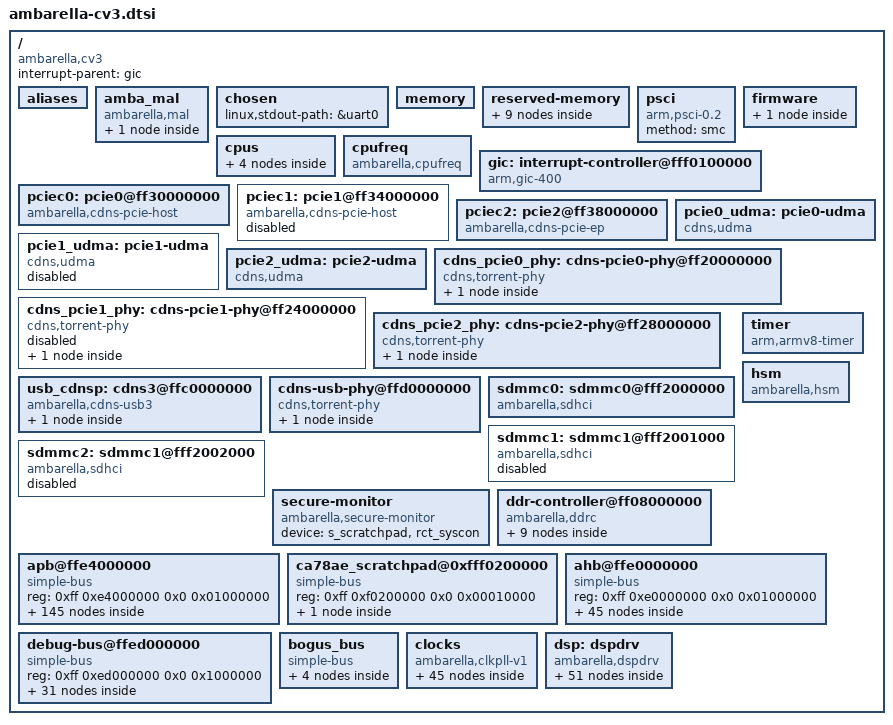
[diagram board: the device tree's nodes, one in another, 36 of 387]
/*
 * chip level device tree source include
 */

/ {
	compatible = "ambarella,cv3";
	interrupt-parent = <&gic>;
	#address-cells = <2>;
	#size-cells = <2>;

	aliases {
		serial0 = &uart0;
		serial1 = &uart1;
		serial2 = &uart2;
		serial3 = &uart3;
		serial4 = &uart4;
		nand = &nand0;
		sd0 = &sdmmc0;
		sd1 = &sdmmc1;
		sd2 = &sdmmc2;
		/* for emmc boot: add emmc alias */
		emmc = &sdmmc0;
		spinor = &spinor0;
		i2c0 = &i2c0;
		i2c1 = &i2c1;
		i2c2 = &i2c2;
		i2c3 = &i2c3;
		i2c4 = &i2c4;
		i2c5 = &i2c5;
		i2cs = &i2cs;
		spi0 = &spi0;
		spi1 = &spi1;
		spi2 = &spi2;
		spi3 = &spi3;
		spi4 = &spi4;
		spi5 = &spi5;
		ethernet0 = &mac0;
		ethernet1 = &mac1;
		ethernet2 = &mac2;
		ethernet3 = &mac3;
		dsp_prot_buf = &dsp_prot_buf;
		dsp_prot_cache_buf = &dsp_prot_cache_buf;
		dsp_bin_buf = &dsp_bin_buf;
		dsp_data_buf = &dsp_data_buf;
		dsp = &dsp;
	};

	amba_mal {
		compatible = "ambarella,mal";
		amb_mal_node@ff {
			memory-region = <&pio>;
			amb_mal_id = <0x07>;
			dedicate-alloc;
		};
	};

	chosen: chosen {
		linux,stdout-path = &uart0;
	};

	/*
	 * the memory node will be overwritten in Amboot,
	 * here is just the default value.
	 */
	memory {
		device_type = "memory";
	};

	reserved-memory {
		#address-cells = <2>;
		#size-cells = <2>;
		device_type = "reserved-memory";
		ranges;

		/* 0~16KB for internal use, like profiling */
		sdk_reserved {
			compatible = "shared-dma-pool";
			no-map;
			reg = <0x0 0x0 0x0 0x4000>;
		};
		pcie0_rmem: pcie0_rmem {
		};
		pcie2_rmem: pcie2_rmem {
		};
		pio: pio {
		};
		xtb {
		};
		dsp_prot_buf: dsp_prot_buf {
		};
		dsp_prot_cache_buf: dsp_prot_cache_buf {
		};
		dsp_bin_buf: dsp_bin_buf {
		};
		dsp_data_buf: dsp_data_buf {
		};
	};

	psci {
		compatible = "arm,psci-0.2";
		method = "smc";
	};

	firmware {
		optee {
			compatible = "linaro,optee-tz";
			method = "smc";
			status = "disabled";
		};
	};

/*
	pmu {
		compatible = "arm,cortex-a78-pmu";
		interrupts = <0 3 0x4>,
			     <0 4 0x4>;
	};
*/

	cpus {
		#address-cells = <1>;
		#size-cells = <0>;

		cpu@0 {
			compatible = "arm,cortex-a78", "arm,armv8";
			device_type = "cpu";
			reg = <0x000>;
			enable-method = "psci";
		};

		cpu@1 {
			compatible = "arm,cortex-a78", "arm,armv8";
			device_type = "cpu";
			reg = <0x100>;
			enable-method = "psci";
		};

		cpu@2 {
			compatible = "arm,cortex-a78", "arm,armv8";
			device_type = "cpu";
			reg = <0x200>;
			enable-method = "psci";
		};

		cpu@3 {
			compatible = "arm,cortex-a78", "arm,armv8";
			device_type = "cpu";
			reg = <0x300>;
			enable-method = "psci";
		};
	};

	cpufreq {
		compatible = "ambarella,cpufreq";

		/*
		 * MASK
		 * + --- + ----- + ----- +
		 * | bit |   1   |   0   |
		 * + --- + ----- + ----- +
		 * | clk |  CORE | CORTEX|
		 * + --- + ----- + ----- +
		 */
		cpufreq-mask = <1>;
		amb,timer-freq-adjust-off;
		clocks = <&gclk_cortex &gclk_core>;
		clock-names = "cortex_clk", "core_clk";
		clocks-frequency-cortex-core =
			<1008000  504000>,
			<816000  336000>,
			<600000  240000>;
	};

	gic: interrupt-controller@fff0100000 {
		compatible = "arm,gic-400";
		#interrupt-cells = <3>;
		#address-cells = <0>;
		#size-cells = <1>;
		interrupt-controller;
		reg = <0xff 0xf0101000 0x0 0x1000>,	/* GIC Dist */
		      <0xff 0xf0102000 0x0 0x2000>,	/* GIC CPU */
		      /* following are not used if no virtulization */
		      <0xff 0xf0104000 0x0 0x2000>,	/* GIC VCPU Control */
		      <0xff 0xf0106000 0x0 0x2000>;	/* GIC VCPU */
		interrupts = <1 9 0xf04>;		/* GIC Maintenence IRQ */
	};

	/*
	 * NOTE: Don't remove "pcie0" in device name("pcie0@ff30000000"),
	 *       it is used to select correct uDMA in endpoint function
	 *       or rc drivers.
	 */
	pciec0: pcie0@ff30000000 {
		compatible = "ambarella,cdns-pcie-host";
		device_type = "pci";
		#address-cells = <3>;
		#size-cells = <2>;
		#interrupt-cells = <1>;
		bus-range = <0 15>;
		linux,pci-domain = <0>;

		reg = <0xff 0x30000000 0x0 0x00600000>,
		      <0xff 0x10000000 0x0 0x00100000>;	/* RC only */
		reg-names = "reg", "cfg";
		memory-region = <&pcie0_rmem>;

		/*
		 * type: 0x01000000 IO
		 * type: 0x02000000 32bit mem space No prefetch
		 * type: 0x03000000 64bit mem space No prefetch
		 * type: 0x43000000 64bit mem space prefetch
		 */
		ranges = <0x02000000 0x00 0x00000000 0xff 0x11000000 0x00 0x01000000>,
			 <0x43000000 0xff 0x12000000 0xff 0x12000000 0x00 0x08000000>;

		interrupt-map-mask = <0x00 0x0 0x0 0x7>;
		interrupt-map = <0x0 0x0 0x0 0x1 &gic 0 202 0x4>,
				<0x0 0x0 0x0 0x2 &gic 0 203 0x4>,
				<0x0 0x0 0x0 0x3 &gic 0 204 0x4>,
				<0x0 0x0 0x0 0x4 &gic 0 205 0x4>;

		cdns,no-bar-match-nbits = <40>;		// RC only
		cdns,max-outbound-regions = <8>;	// EP only
		max-functions = /bits/ 8 <1>;		// EP only

		amb,scr-regmap = <&n_scratchpad_syscon 0x1ac>;
		phys = <&pcie0_phy>;
		phy-names="pcie-phy";
	};

	/*
	 * NOTE: Don't remove "pcie1" in device name("pcie1@ff34000000"),
	 *       it is used to select correct uDMA in endpoint function
	 *       or rc drivers.
	 */
	pciec1: pcie1@ff34000000 {
		compatible = "ambarella,cdns-pcie-host";
		device_type = "pci";
		#address-cells = <3>;
		#size-cells = <2>;
		#interrupt-cells = <1>;
		bus-range = <0 15>;
		linux,pci-domain = <1>;

		reg = <0xff 0x34000000 0x0 0x00600000>,
		      <0xff 0x50000000 0x0 0x00100000>;
		reg-names = "reg", "cfg";

		ranges = <0x02000000 0x00 0x00000000 0xff 0x51000000 0x00 0x01000000>,
			 <0x43000000 0xff 0x52000000 0xff 0x52000000 0x00 0x08000000>;

		interrupt-map-mask = <0x00 0x0 0x0 0x7>;
		interrupt-map = <0x0 0x0 0x0 0x1 &gic 0 216 0x4>,
				<0x0 0x0 0x0 0x2 &gic 0 217 0x4>,
				<0x0 0x0 0x0 0x3 &gic 0 218 0x4>,
				<0x0 0x0 0x0 0x4 &gic 0 219 0x4>;

		cdns,no-bar-match-nbits = <40>;

		amb,scr-regmap = <&n_scratchpad_syscon 0x1b0>;
		phys = <&pcie1_phy>;
		phy-names="pcie-phy";

		status = "disabled";
	};

	/*
	 * NOTE: Don't remove "pcie2" in device name("pcie2@ff38000000"),
	 *       it is used to select correct uDMA in endpoint function
	 *       or rc drivers.
	 */
	pciec2: pcie2@ff38000000 {
		compatible = "ambarella,cdns-pcie-ep";
		device_type = "pci";
		#address-cells = <3>;
		#size-cells = <2>;
		#interrupt-cells = <1>;
		bus-range = <0 15>;
		linux,pci-domain = <2>;

		reg = <0xff 0x38000000 0x0 0x00600000>,
		      <0xff 0x90000000 0x0 0x30000000>;
		reg-names = "reg", "mem";
		memory-region = <&pcie2_rmem>;

		interrupt-map-mask = <0x00 0x0 0x0 0x7>;
		interrupt-map = <0x0 0x0 0x0 0x1 &gic 0 230 0x4>,
				<0x0 0x0 0x0 0x2 &gic 0 231 0x4>,
				<0x0 0x0 0x0 0x3 &gic 0 232 0x4>,
				<0x0 0x0 0x0 0x4 &gic 0 233 0x4>;

		cdns,no-bar-match-nbits = <40>;		// RC only

		amb,scr-regmap = <&n_scratchpad_syscon 0x1b4>;
		phys = <&pcie2_phy>;
		phy-names="pcie-phy";

		status = "okay";
	};

	pcie0_udma: pcie0-udma {
		#address-cells = <2>;
		#size-cells = <2>;
		compatible = "cdns,udma";
		interrupts = <0 200 0x4>;
		reg = <0xff 0x30600000 0x0 0x000000fc>;
		status = "okay";
	};

	pcie1_udma: pcie1-udma {
		#address-cells = <2>;
		#size-cells = <2>;
		compatible = "cdns,udma";
		interrupts = <0 214 0x4>;
		reg = <0xff 0x34600000 0x0 0x000000fc>;
		status = "disabled";
	};

	pcie2_udma: pcie2-udma {
		#address-cells = <2>;
		#size-cells = <2>;
		compatible = "cdns,udma";
		interrupts = <0 228 0x4>;
		reg = <0xff 0x38600000 0x0 0x000000fc>;
		status = "okay";
	};

	cdns_pcie0_phy: cdns-pcie0-phy@ff20000000 {
		compatible = "cdns,torrent-phy";
		#address-cells = <1>;
		#size-cells = <0>;
		reg = <0xff 0x20000000 0x0 0x04000000>;

		resets = <&pcie0_phyrst 0>;
		reset-names = "torrent_reset";

		clocks = <&cdns_phy_refclk>;
		clock-names = "refclk";

		pcie0_phy: phy@0 {
			reg = <0>;
			resets=<&pcie0_phyrst 1>;	// link reset not used
			#phy-cells= <0>;
			cdns,phy-type = <2>;		// TYPE_PCIE
			cdns,num-lanes = <4>;
			cdns,ssc-mode = <0>;		// NO_SSC
		};
	};

	cdns_pcie1_phy: cdns-pcie1-phy@ff24000000 {
		compatible = "cdns,torrent-phy";
		#address-cells = <1>;
		#size-cells = <0>;
		reg = <0xff 0x24000000 0x0 0x04000000>;

		resets = <&pcie1_phyrst 0>;
		reset-names = "torrent_reset";

		clocks = <&cdns_phy_refclk>;
		clock-names = "refclk";

		status = "disabled";

		pcie1_phy: phy@0 {
			reg = <0>;
			resets=<&pcie1_phyrst 1>;	// link reset not used
			#phy-cells= <0>;
			cdns,phy-type = <2>;		// TYPE_PCIE
			cdns,num-lanes = <4>;
			cdns,ssc-mode = <0>;		// NO_SSC
		};
	};

	cdns_pcie2_phy: cdns-pcie2-phy@ff28000000 {
		compatible = "cdns,torrent-phy";
		#address-cells = <1>;
		#size-cells = <0>;
		reg = <0xff 0x28000000 0x0 0x04000000>;

		resets = <&pcie2_phyrst 0>;
		reset-names = "torrent_reset";

		clocks = <&cdns_phy_refclk>;
		clock-names = "refclk";

		status = "okay";

		pcie2_phy: phy@0 {
			reg = <0>;
			resets=<&pcie2_phyrst 1>;	// link reset not used
			#phy-cells= <0>;
			cdns,phy-type = <2>;		// TYPE_PCIE
			cdns,num-lanes = <4>;
			cdns,ssc-mode = <0>;		// NO_SSC
		};
	};

	usb_cdnsp: cdns3@ffc0000000 {
		compatible = "ambarella,cdns-usb3";
		#address-cells = <2>;
		#size-cells = <2>;
		reg = <0xff 0xc0000000 0x0 0x10000000>;
		ranges;
		amb,scr-regmap = <&n_scratchpad_syscon>;

		cdns3: cdns3 {
			compatible = "cdns,usb3";
			interrupts = <0 190 0x4>, <0 190 0x4>, <0 190 0x4>;
			interrupt-names = "host", "peripheral", "otg";
			reg = <0xff 0xc0008000 0x0 0x4000>,
			      <0xff 0xc0004000 0x0 0x4000>,
			      <0xff 0xc0000000 0x0 0x4000>;
			reg-names = "xhci", "dev", "otg";
			dr_mode = "otg";
			phys = <&usb32_phy>;
			phy-names = "cdns3,usb3-phy";
			maximum-speed = "super-speed-plus";
			usb-role-switch;
		};
	};

	cdns-usb-phy@ffd0000000 {
		compatible = "cdns,torrent-phy";
		#address-cells = <1>;
		#size-cells = <0>;
		reg = <0xff 0xd0000000 0x0 0x00100000>;

		clocks = <&cdns_phy_refclk>;
		clock-names = "refclk";

		resets = <&usb32_phyrst 0>;
		reset-names = "torrent_reset";

		usb32_phy: phy@0 {
			reg = <0>;
			resets = <&usb32_phyrst 1>;
			#phy-cells = <0>;
			cdns,phy-type = <4>;	/* TYPE_USB */
			cdns,num-lanes = <1>;
			cdns,ssc-mode = <2>;	/* INTERNAL_SSC */
		};
	};

	sdmmc0: sdmmc0@fff2000000 {
		compatible = "ambarella,sdhci";
		//Modify start byte addr and size to 64bits.
		#address-cells = <2>;
		#size-cells = <2>;
		reg = <0xff 0xf2000000 0x0 0x1000>;
		interrupts = <0 109 0x4>;
		clocks = <&gclk_sd0>;
		bus-width = <8>;
		cap-sdio-irq;
		cap-sd-highspeed;
		cap-mmc-highspeed;
		mmc-hs200-1_8v;
	};

	sdmmc1: sdmmc1@fff2001000 { /* SDIO0 */
		compatible = "ambarella,sdhci";
		reg = <0xff 0xf2001000 0x0 0x1000>;
		interrupts = <0 110 0x4>;
		clocks = <&gclk_sd1>;
		bus-width = <4>;
		cap-sdio-irq;
		cap-sd-highspeed;
		cap-mmc-highspeed;
		status = "disabled";
	};

	sdmmc2: sdmmc1@fff2002000 { /* SDIO1 */
		compatible = "ambarella,sdhci";
		reg = <0xff 0xf2002000 0x0 0x1000>;
		interrupts = <0 111 0x4>;
		clocks = <&gclk_sd2>;
		bus-width = <4>;
		cap-sdio-irq;
		cap-sd-highspeed;
		cap-mmc-highspeed;
		status = "disabled";
	};

	timer {
		compatible = "arm,armv8-timer";
		interrupts = <1 13 0xf08>,	/* Secure Phys IRQ */
			     <1 14 0xf08>,	/* Non-secure Phys IRQ */
			     <1 11 0xf08>,	/* Virt IRQ */
			     <1 10 0xf08>;	/* Hyp IRQ */
	};

	secure-monitor {
		compatible = "ambarella,secure-monitor";
		#address-cells = <1>;
		#size-cells = <0>;
		device = <&s_scratchpad &rct_syscon>;
	};

	ddr-controller@ff08000000 {
		compatible = "ambarella,ddrc";
		#address-cells = <1>;
		#size-cells = <1>;
		reg = <0xff 0x08000000 0x0 0x80000>;
		burst-size = <0>;		/* This property will be overwritten in AMBOOT. */

		dramc: dramc@08000000 {
			reg = <0x08000000 0x1000>;
        };

        /* DDR host controller cluster */
		ddrhc0: ddrhc0@08014000 {
			reg = <0x08014000 0x2000>;
			compatible = "ambarella,dtte";
			interrupts = <0 254 0x4>;
			interrupt-names = "dtte0";
        };
		ddrhc1: ddrhc1@08020000 {
			reg = <0x08020000 0x2000>;
			compatible = "ambarella,dtte";
			interrupts = <0 255 0x4>;
			interrupt-names = "dtte1";
        };
		ddrhc2: ddrhc2@0802c000 {
			reg = <0x0802c000 0x2000>;
			compatible = "ambarella,dtte";
			interrupts = <0 256 0x4>;
			interrupt-names = "dtte2";
        };
		ddrhc3: ddrhc3@08038000 {
			reg = <0x08038000 0x2000>;
			compatible = "ambarella,dtte";
			interrupts = <0 257 0x4>;
			interrupt-names = "dtte3";
        };
		ddrhc4: ddrhc4@08044000 {
			reg = <0x08044000 0x2000>;
			compatible = "ambarella,dtte";
			interrupts = <0 258 0x4>;
			interrupt-names = "dtte4";
        };
		ddrhc5: ddrhc5@08050000 {
			reg = <0x08050000 0x2000>;
			compatible = "ambarella,dtte";
			interrupts = <0 259 0x4>;
			interrupt-names = "dtte5";
        };
		ddrhc6: ddrhc6@0805c000 {
			reg = <0x0805c000 0x2000>;
			compatible = "ambarella,dtte";
			interrupts = <0 260 0x4>;
			interrupt-names = "dtte6";
        };
		ddrhc7: ddrhc7@08068000 {
			reg = <0x08068000 0x2000>;
			compatible = "ambarella,dtte";
			interrupts = <0 261 0x4>;
			interrupt-names = "dtte7";
        };
	};

	apb@ffe4000000 {
		compatible = "simple-bus";
		#address-cells = <1>;
		#size-cells = <1>;
		reg = <0xff 0xe4000000 0x0 0x01000000>;
		ranges = <0xe4000000 0xff 0xe4000000 0x01000000>;

		clocksource1: timer@e4004054 {	/* timer6 */
			compatible = "ambarella,clock-source";
			reg = <0xe4004054 0x10 0xe4004030 0x4>;
			interrupts = <0 158 0x1>;
			ctrl-offset = <20>; /* bit offset in timer-ctrl reg */
			clocks = <&gclk_apb>;
			status = "disabled";
		};

		clockevent1: timer@e4004064 {	/* timer7, timer8, timer9, timer10 */
			compatible = "ambarella,local-clock-event";
			reg = <0xe4004064 0x10 0xe4004030 0x4>,
			      <0xe4004074 0x10 0xe4004030 0x4>,
			      <0xe4004088 0x10 0xe4004084 0x4>,
			      <0xe4004098 0x10 0xe4004084 0x4>;
			interrupts = <0 159 0x1>, <0 160 0x1>, <0 161 0x1>, <0 162 0x1>;
			ctrl-offset = <24 28 00 04>; /* bit offset in timer-ctrl reg */
			clocks = <&gclk_apb>;
			status = "disabled";
		};

		clocksource2: timer@e4005054 {	/* timer16 */
			compatible = "ambarella,clock-source";
			reg = <0xe4005054 0x10 0xe4005030 0x4>;
			interrupts = <0 168 0x1>;
			ctrl-offset = <20>; /* bit offset in timer-ctrl reg */
			clocks = <&gclk_apb>;
			status = "disabled";
		};

		clockevent2: timer@e4005064 {	/* timer17, timer18, timer19, timer20 */
			compatible = "ambarella,local-clock-event";
			reg = <0xe4005064 0x10 0xe4005030 0x4>,
			      <0xe4005074 0x10 0xe4005030 0x4>,
			      <0xe4005088 0x10 0xe4005084 0x4>,
			      <0xe4005098 0x10 0xe4005084 0x4>;
			interrupts = <0 169 0x1>, <0 170 0x1>, <0 171 0x1>, <0 172 0x1>;
			ctrl-offset = <24 28 00 04>; /* bit offset in timer-ctrl reg */
			clocks = <&gclk_apb>;
			status = "disabled";
		};

		clocksource3: timer@e4006054 {	/* timer26 */
			compatible = "ambarella,clock-source";
			reg = <0xe4006054 0x10 0xe4006030 0x4>;
			interrupts = <0 464 0x1>;
			ctrl-offset = <20>; /* bit offset in timer-ctrl reg */
			clocks = <&gclk_apb>;
			status = "disabled";
		};

		clockevent3: timer@e4006044 {	/* timer27, timer28, timer29, timer30 */
			compatible = "ambarella,local-clock-event";
			reg = <0xe4006064 0x10 0xe4006030 0x4>,
			      <0xe4006074 0x10 0xe4006030 0x4>,
			      <0xe4006088 0x10 0xe4006084 0x4>,
			      <0xe4006098 0x10 0xe4006084 0x4>;
			interrupts = <0 465 0x1>, <0 466 0x1>, <0 467 0x1>, <0 468 0x1>;
			ctrl-offset = <24 28 00 04>; /* bit offset in timer-ctrl reg */
			clocks = <&gclk_apb>;
			status = "disabled";
		};

		uart0: uart@e4000000 {
			compatible = "ambarella,uart";
			reg = <0xe4000000 0x1000>;
			interrupts = <0 187 0x4>;
			pinctrl-names = "default";
			pinctrl-0 = <&uart0_pins>;
			clocks = <&gclk_uart0>;
			status = "ok";
		};

		ir@e4001000 {
			compatible = "ambarella,ir";
			reg = <0xe4001000 0x1000>;
			interrupts = <0 189 0x4>;
			pinctrl-names = "default";
			pinctrl-0 = <&ir_pins_a>;
			clocks = <&gclk_ir>;
			status = "disabled";
		};

		i2c0: i2c@e4008000 {
			compatible = "ambarella,i2c";
			#address-cells = <1>;
			#size-cells = <0>;
			reg = <0xe4008000 0x1000>;
			interrupts = <0 173 0x4>;
			pinctrl-names = "default";
			pinctrl-0 = <&i2c0_pins>;
			clocks = <&gclk_apb>;
			clock-frequency = <100000>;
			amb,i2c-class = <0x81>;
			status = "disabled";
		};

		i2c1: i2c@e4009000 {
			compatible = "ambarella,i2c";
			#address-cells = <1>;
			#size-cells = <0>;
			reg = <0xe4009000 0x1000>;
			interrupts = <0 174 0x4>;
			pinctrl-names = "default";
			pinctrl-0 = <&i2c1_pins_c>;
			clocks = <&gclk_apb>;
			clock-frequency = <100000>;
			amb,i2c-class = <0x08>;
			status = "disabled";
		};

		i2c2: i2c@e400a000 {
			compatible = "ambarella,i2c";
			#address-cells = <1>;
			#size-cells = <0>;
			reg = <0xe400a000 0x1000>;
			interrupts = <0 175 0x4>;
			clocks = <&gclk_apb>;
			pinctrl-names = "default";
			pinctrl-0 = <&i2c2_pins_b>;
			clock-frequency = <100000>;
			amb,i2c-class = <0x81>;
			status = "disabled";
		};

		i2c3: i2c@e400b000 {
			compatible = "ambarella,i2c";
			#address-cells = <1>;
			#size-cells = <0>;
			reg = <0xe400b000 0x1000>;
			interrupts = <0 176 0x4>;
			clocks = <&gclk_apb>;
			pinctrl-names = "default";
			pinctrl-0 = <&i2c3_pins_a>;
			clock-frequency = <100000>;
			amb,i2c-class = <0x81>;
			status = "disabled";
		};

		i2c4: i2c@e400e000 {
			compatible = "ambarella,i2c";
			#address-cells = <1>;
			#size-cells = <0>;
			reg = <0xe400e000 0x1000>;
			interrupts = <0 177 0x4>;
			clocks = <&gclk_apb>;
			pinctrl-names = "default";
			pinctrl-0 = <&i2c4_pins_a>;
			clock-frequency = <100000>;
			amb,i2c-class = <0x81>;
			status = "disabled";
		};

		i2c5: i2c@e400f000 {
			compatible = "ambarella,i2c";
			#address-cells = <1>;
			#size-cells = <0>;
			reg = <0xe400f000 0x1000>;
			interrupts = <0 178 0x4>;
			clocks = <&gclk_apb>;
			pinctrl-names = "default";
			pinctrl-0 = <&i2c5_pins_c>;
			clock-frequency = <100000>;
			amb,i2c-class = <0x81>;
			status = "disabled";
		};

		i2cs: i2cs@e4007000 {
			compatible = "ambarella,i2cs";
			#address-cells = <1>;
			#size-cells = <0>;
			reg = <0xe4007000 0x1000>;
			interrupts = <0 179 0x4>;
			clocks = <&gclk_apb>;
			pinctrl-names = "default";
			pinctrl-0 = <&i2cs0_pins>;
			status = "disabled";
		};

		pwm0: pwm@e4003000 {
			compatible = "ambarella,pwm";
			reg = <0xe4003000 0x1000>;
			clock-frequency = <2000000>;
			clocks = <&gclk_pwm>;
			#pwm-cells = <3>;
		};

		pwm1: pwm@e400c000 {
			compatible = "ambarella,pwm";
			reg = <0xe400c000 0x1000>;
			clock-frequency = <2000000>;
			clocks = <&gclk_pwm>;
			#pwm-cells = <3>;
		};

		pwm2: pwm@e400d000 {
			compatible = "ambarella,pwm";
			reg = <0xe400d000 0x1000>;
			clock-frequency = <2000000>;
			clocks = <&gclk_pwm>;
			#pwm-cells = <3>;
		};

		watchdog0: wdt@e401a000 {
			compatible = "ambarella,wdt";
			reg = <0xe401a000 0x1000>;
			/* interrupts = <0 469 0x4>; */
			timeout-sec = <15>;
			amb,rct-regmap = <&rct_syscon>;
			amb,secure-ctrl-bit = <117>;
		};

		watchdog1: wdt@e401b000 {
			compatible = "ambarella,wdt";
			reg = <0xe401b000 0x1000>;
			/* interrupts = <0 470 0x4>; */
			timeout-sec = <15>;
			amb,rct-regmap = <&rct_syscon>;
			amb,secure-ctrl-bit = <118>;
		};

		watchdog2: wdt@e401c000 {
			compatible = "ambarella,wdt";
			reg = <0xe401c000 0x1000>;
			/* interrupts = <0 471 0x4>; */
			timeout-sec = <15>;
			amb,rct-regmap = <&rct_syscon>;
			amb,secure-ctrl-bit = <119>;
		};

		watchdog3: wdt@e401d000 {
			compatible = "ambarella,wdt";
			reg = <0xe401d000 0x1000>;
			/* interrupts = <0 472 0x4>; */
			timeout-sec = <15>;
			amb,rct-regmap = <&rct_syscon>;
			amb,secure-ctrl-bit = <120>;
		};

		watchdog4: wdt@e401e000 {
			compatible = "ambarella,wdt";
			reg = <0xe401e000 0x1000>;
			/* interrupts = <0 473 0x4>; */
			timeout-sec = <15>;
			amb,rct-regmap = <&rct_syscon>;
			amb,secure-ctrl-bit = <121>;
		};

		watchdog5: wdt@e401f000 {
			compatible = "ambarella,wdt";
			reg = <0xe401f000 0x1000>;
			/* interrupts = <0 474 0x4>; */
			timeout-sec = <15>;
			amb,rct-regmap = <&rct_syscon>;
			amb,secure-ctrl-bit = <122>;
		};

		watchdog6: wdt@e4020000 {
			compatible = "ambarella,wdt";
			reg = <0xe4020000 0x1000>;
			/* interrupts = <0 475 0x4>; */
			timeout-sec = <15>;
			amb,rct-regmap = <&rct_syscon>;
			amb,secure-ctrl-bit = <123>;
		};

		watchdog7: wdt@e4021000 {
			compatible = "ambarella,wdt";
			reg = <0xe4021000 0x1000>;
			/* interrupts = <0 476 0x4>; */
			timeout-sec = <15>;
			amb,rct-regmap = <&rct_syscon>;
			amb,secure-ctrl-bit = <124>;
		};

		pinctrl: pinctrl@e4010000 {
			compatible = "ambarella,pinctrl";
			#address-cells = <1>;
			#size-cells = <0>;
			reg = <0xe4013000 0x1000>,
			      <0xe4014000 0x1000>,
			      <0xe4015000 0x1000>,
			      <0xe4016000 0x1000>,
			      <0xe4017000 0x1000>,
			      <0xe4018000 0x1000>,
			      <0xe4019000 0x1000>,
			      <0xe4010000 0x1000>;
			reg-names = "gpio0", "gpio1", "gpio2", "gpio3", "gpio4","gpio5","gpio6","iomux";
			interrupts = <0 180 0x4>,
				     <0 181 0x4>,
				     <0 182 0x4>,
				     <0 183 0x4>,
				     <0 184 0x4>,
				     <0 185 0x4>,
				     <0 186 0x4>;
			amb,pull-regmap = <&s_scratchpad 0x60 0x7c>;
			amb,ds-regmap = <&rct_syscon>;
			amb,secure-ctrl-bit = <50 51 52 53 54 59 37 48>;

			gpio: gpio@0 {
				reg = <0>;
				gpio-controller;
				#gpio-cells = <2>;
				gpio-ranges = <&pinctrl 0 0 213>;
				interrupt-controller;
				#interrupt-cells = <2>;
			};

			uart0_pins: uart0@0 {
				reg = <0>;
				amb,pinmux-ids = <0x102d 0x102e>;
			};

			uart1_pins_a: uart1@0 {		/* UART0_AHB_TX/RX */
				reg = <0>;
				amb,pinmux-ids = <0x3050 0x3051>;
			};

			uart1_pins_b: uart1@1 {
				reg = <1>;
				amb,pinmux-ids = <0x109f 0x10a0>;
			};

			uart1_flow_pins_a: uart1_flow@0 {
				reg = <0>;
				amb,pinmux-ids = <0x3053 0x3054>;
			};

			uart1_flow_pins_b: uart1_flow@1 {
				reg = <1>;
				amb,pinmux-ids = <0x10a1 0x10a2>;
			};

			uart2_pins_a: uart2@0 {		/* UART1_AHB_RX/RX */
				reg = <0>;
				amb,pinmux-ids = <0x10a3 0x10a4>;
			};

			uart2_pins_b: uart2@1 {
				reg = <1>;
				amb,pinmux-ids = <0x30a7 0x30a8>;
			};

			uart2_flow_pins_a: uart2_flow@0 {
				reg = <0>;
				amb,pinmux-ids = <0x10a5 0x10a6>;
			};

			uart2_flow_pins_b: uart2_flow@1 {
				reg = <1>;
				amb,pinmux-ids = <0x30a9 0x30aa>;
			};

			uart3_pins_a: uart3@0 {		/* UART2_AHB_RX/RX */
				reg = <0>;
				amb,pinmux-ids = <0x207a 0x207b>;
			};

			uart3_pins_b: uart3@1 {
				reg = <1>;
				amb,pinmux-ids = <0x2084 0x2085>;
			};

			uart3_pins_c: uart3@2 {
				reg = <2>;
				amb,pinmux-ids = <0x20cf 0x20d0>;
			};

			uart3_flow_pins_a: uart3_flow@0 {
				reg = <0>;
				amb,pinmux-ids = <0x207c 0x207d>;
			};

			uart3_flow_pins_b: uart3_flow@1 {
				reg = <1>;
				amb,pinmux-ids = <0x2086 0x2087>;
			};

			uart3_flow_pins_c: uart3_flow@2 {
				reg = <2>;
				amb,pinmux-ids = <0x20d1 0x20d2>;
			};

			uart4_pins_a: uart4@0 {		/* UART3_AHB_RX/RX */
				reg = <0>;
				amb,pinmux-ids = <0x2089 0x208a>;
			};

			uart4_pins_b: uart4@1 {
				reg = <1>;
				amb,pinmux-ids = <0x406a 0x406b>;
			};

			uart4_pins_c: uart4@2 {
				reg = <2>;
				amb,pinmux-ids = <0x30cf 0x30d0>;
			};

			uart4_flow_pins_a: uart4_flow@0 {
				reg = <0>;
				amb,pinmux-ids = <0x208b 0x208c>;
			};

			uart4_flow_pins_b: uart4_flow@1 {
				reg = <1>;
				amb,pinmux-ids = <0x406c 0x406d>;
			};

			uart4_flow_pins_c: uart4_flow@2 {
				reg = <2>;
				amb,pinmux-ids = <0x30d1 0x30d2>;
			};

			snand_pins: snand@0 {
				reg = <0>;
				amb,pinmux-ids = <0x1078 0x1079 0x107a 0x107b
						  0x107c 0x107d>;
			};

			spinor_pins: spinor@0 {
				reg = <0>;
				amb,pinmux-ids = <0x107e 0x107f 0x1080 0x1081
						  0x1082 0x1083 0x1084 0x1085
						  0x1086 0x1087 0x1088>;
			};

			sdmmc0_reset_pin: sdmmc0_reset@0 {
				reg = <0>;
				amb,pinmux-ids = <0x1090>;
			};

			sdmmc1_reset_pin: sdmmc1_reset@0 {
				reg = <0>;
				amb,pinmux-ids = <0x1092>;
			};

			sdmmc2_reset_pin: sdmmc2_reset@0 {
				reg = <0>;
				amb,pinmux-ids = <0x1094>;
			};

			enet_ext_osc_clk: enet-ext-osc-clk@0 {	/* shared by enet0/1/2/3 125MHZ input refclock */
				reg = <0>;
				amb,pinmux-ids = <0x2049>;
			};

			enet_2nd_ref_clk_a: enet-2nd-ref-clk@0 {
				reg = <0>;
				amb,pinmux-ids = <0x1048>;
			};

			enet_2nd_ref_clk_b: enet-2nd-ref-clk@1 {
				reg = <1>;
				amb,pinmux-ids = <0x104a>;
			};

			enet_2nd_ref_clk_c: enet-2nd-ref-clk@2 {
				reg = <2>;
				amb,pinmux-ids = <0x204a>;
			};

			enet_2nd_ref_clk_d: enet-2nd-ref-clk@3 {
				reg = <3>;
				amb,pinmux-ids = <0x1059>;
			};

			enet_2nd_ref_clk_e: enet-2nd-ref-clk@4 {
				reg = <4>;
				amb,pinmux-ids = <0x1068>;
			};

			enet_2nd_ref_clk_f: enet-2nd-ref-clk@5 {
				reg = <5>;
				amb,pinmux-ids = <0x1077>;
			};

			rgmii0_pins: eth0@0 {	/* ethernet-mac0 */
				reg = <0>;
				amb,pinmux-ids = <0x203a 0x203b 0x203c 0x203d
						  0x203e 0x203f 0x2040 0x2041
						  0x2042 0x2043	0x3044 0x3045
						  0x2047 0x2048>;
			};

			rmii0_pins: eth0@1 {
				reg = <1>;
				amb,pinmux-ids = <0x103a 0x103b 0x103c 0x103f
						  0x1040 0x1043 0x3044 0x3045 0x1047>;
			};

			rgmii0_ptp_pps_o: enet0-ptp-pps-o@0 {
				reg = <0>;
				amb,pinmux-ids = <0x2046>;
			};

			rmii0_ptp_pps_o: enet0-ptp-pps-o@1 {
				reg = <1>;
				amb,pinmux-ids = <0x1046>;
			};

			rgmii1_pins: eth1@0 {	/* ethernet-mac1 */
				reg = <0>;
				amb,pinmux-ids = <0x204b 0x204c 0x204d 0x204e
						  0x204f 0x2050 0x2051 0x2052
						  0x2053 0x2054 0x3055 0x3056
						  0x2058 0x2059>;

			};

			rmii1_pins: eth1@1 {
				reg = <1>;
				amb,pinmux-ids = <0x104b 0x104c 0x104d 0x1050
						  0x1051 0x1054 0x3055 0x3056
						  0x1058>;
			};

			rgmii1_ptp_pps_o: enet1-ptp-pps-o@0 {
				reg = <0>;
				amb,pinmux-ids = <0x2057>;
			};

			rmii1_ptp_pps_o: enet1-ptp-pps-o@1 {
				reg = <1>;
				amb,pinmux-ids = <0x1057>;
			};

			rgmii2_pins: eth2@0 {	/* ethernet-mac2 */
				reg = <0>;
				amb,pinmux-ids = <0x205a 0x205b 0x205c 0x205d
						  0x205e 0x205f 0x2060 0x2061
						  0x2062 0x2063 0x3064 0x3065
						  0x2067 0x2068>;
			};

			rmii2_pins: eth2@1 {
				reg = <1>;
				amb,pinmux-ids = <0x105a 0x105b 0x105c 0x105f
						  0x1060 0x1063 0x3064 0x3065
						  0x1067>;
			};

			rgmii2_ptp_pps_o: enet2-ptp-pps-o@0 {
				reg = <0>;
				amb,pinmux-ids = <0x2066>;
			};

			rmii2_ptp_pps_o: enet2-ptp-pps-o@1 {
				reg = <1>;
				amb,pinmux-ids = <0x1066>;
			};

			rgmii3_pins: eth3@0 {	/* ethernet-mac3 */
				reg = <0>;
				amb,pinmux-ids = <0x2069 0x206a 0x206b 0x206c
						  0x206d 0x206e 0x206f 0x2070
						  0x2071 0x2072 0x3073 0x3074
						  0x2076 0x2077>;
			};

			rmii3_pins: eth3@1 {
				reg = <1>;
				amb,pinmux-ids = <0x1069 0x106a 0x106b 0x106e
						  0x106f 0x1072 0x3073 0x3074
						  0x1076>;
			};

			rgmii3_ptp_pps_o: enet3-ptp-pps-o@0 {
				reg = <0>;
				amb,pinmux-ids = <0x2075>;
			};

			rmii3_ptp_pps_o: enet3-ptp-pps-o@1 {
				reg = <1>;
				amb,pinmux-ids = <0x1075>;
			};

			i2c0_pins: i2c0@0 {
				reg = <0>;
				amb,pinmux-ids = <0x109a 0x109b>;
			};

			i2c1_pins_a: i2c1@0 {
				reg = <0>;
				amb,pinmux-ids = <0x2002 0x2003>;
			};

			i2c1_pins_b: i2c1@1 {
				reg = <1>;
				amb,pinmux-ids = <0x405f 0x4060>;
			};

			i2c1_pins_c: i2c1@2 {
				reg = <2>;
				amb,pinmux-ids = <0x40cf 0x40d0>;
			};

			i2c2_pins_a: i2c2@0 {
				reg = <0>;
				amb,pinmux-ids = <0x2004 0x2005>;
			};

			i2c2_pins_b: i2c2@1 {
				reg = <1>;
				amb,pinmux-ids = <0x1098 0x1099>;
			};

			i2c2_pins_c: i2c2@2 {
				reg = <2>;
				amb,pinmux-ids = <0x40d1 0x40d2>;
			};

			i2c3_pins_a: i2c3@0 {
				reg = <0>;
				amb,pinmux-ids = <0x200b 0x200c>;
			};

			i2c3_pins_b: i2c3@1 {
				reg = <1>;
				amb,pinmux-ids = <0x20a5 0x20a6>;
			};

			i2c3_pins_c: i2c3@2 {
				reg = <2>;
				amb,pinmux-ids = <0x50a7 0x50a8>;
			};

			i2c4_pins_a: i2c4@0 {
				reg = <0>;
				amb,pinmux-ids = <0x200d 0x200e>;
			};

			i2c4_pins_b: i2c4@1 {
				reg = <1>;
				amb,pinmux-ids = <0x4050 0x4051>;
			};

			i2c4_pins_c: i2c4@2 {
				reg = <2>;
				amb,pinmux-ids = <0x4061 0x4062>;
			};

			i2c5_pins_a: i2c5@0 {
				reg = <0>;
				amb,pinmux-ids = <0x4052 0x4053>;
			};

			i2c5_pins_b: i2c5@1 {
				reg = <1>;
				amb,pinmux-ids = <0x5066 0x5067>;
			};

			i2c5_pins_c: i2c5@2 {
				reg = <2>;
				amb,pinmux-ids = <0x30a5 0x30a6>;
			};

			i2cs0_pins: i2cs0@0 {
				reg = <0>;
				amb,pinmux-ids = <0x1013 0x1014>;
			};

			can0_pins: can0@0 {
				reg = <0>;
				amb,pinmux-ids = <0x10a7 0x10a8>;
			};

			can1_pins: can1@0 {
				reg = <0>;
				amb,pinmux-ids = <0x10a9 0x10aa>;
			};

			ir_pins_a: ir0@0 {
				reg = <0>;
				amb,pinmux-ids = <0x1000>;
			};

			ir_pins_b: ir0@1 {
				reg = <1>;
				amb,pinmux-ids = <0x5058>;
			};

			ir_pins_c: ir0@2 {
				reg = <2>;
				amb,pinmux-ids = <0x3063>;
			};

			wdt_pins_a: wdt0@0 {
				reg = <0>;
				amb,pinmux-ids = <0x2000>;
			};

			wdt_pins_b: wdt0@1 {
				reg = <1>;
				amb,pinmux-ids = <0x2001>;
			};

			wdt_pins_c: wdt0@2 {
				reg = <2>;
				amb,pinmux-ids = <0x2006>;
			};

			wdt_pins_d: wdt0@3 {
				reg = <3>;
				amb,pinmux-ids = <0x303a>;
			};

			wdt_pins_e: wdt0@4 {
				reg = <4>;
				amb,pinmux-ids = <0x304b>;
			};

			wdt_pins_f: wdt0@5 {
				reg = <5>;
				amb,pinmux-ids = <0x209c>;
			};

			wdt_pins_g: wdt0@6 {
				reg = <6>;
				amb,pinmux-ids = <0x409f>;
			};

			wdt_pins_h: wdt0@7 {
				reg = <7>;
				amb,pinmux-ids = <0x40d4>;
			};

			i2s0_pins: i2s0@0 {
				reg = <0>;
				amb,pinmux-ids = <0x1032 0x1033 0x1034 0x1035>;
			};

			i2s1_pins: i2s1@0 {
				reg = <0>;
				amb,pinmux-ids = <0x1036 0x1037 0x1038 0x1039>;
			};

			dmic0_pins: dmic_pins@0 {
				reg = <0>;
				amb,pinmux-ids = <0x2032 0x2033>;
			};

			pwm0_pins: pwm0@0 {
				reg = <0>;
				amb,pinmux-ids = <0x102f>;
			};

			pwm1_pins: pwm1@0 {
				reg = <0>;
				amb,pinmux-ids = <0x1030>;
			};

			pwm2_pins: pwm2@0 {
				reg = <0>;
				amb,pinmux-ids = <0x1031>;
			};

			pwm3_pins_a: pwm3@0 {
				reg = <0>;
				amb,pinmux-ids = <0x2007>;
			};

			pwm3_pins_b: pwm3@1 {
				reg = <1>;
				amb,pinmux-ids = <0x2029>;
			};

			pwm4_pins_a: pwm4@0 {
				reg = <0>;
				amb,pinmux-ids = <0x2008>;
			};

			pwm4_pins_b: pwm4@1 {
				reg = <1>;
				amb,pinmux-ids = <0x202a>;
			};

			pwm5_pins_a: pwm5@0 {
				reg = <0>;
				amb,pinmux-ids = <0x2009>;
			};

			pwm5_pins_b: pwm5@1 {
				reg = <1>;
				amb,pinmux-ids = <0x202b>;
			};

			pwm6_pins_a: pwm6@0 {
				reg = <0>;
				amb,pinmux-ids = <0x200a>;
			};

			pwm6_pins_b: pwm6@1 {
				reg = <1>;
				amb,pinmux-ids = <0x202c>;
			};

			pwm7_pins_a: pwm7@0 {
				reg = <0>;
				amb,pinmux-ids = <0x2015>;
			};

			pwm7_pins_b: pwm7@1 {
				reg = <1>;
				amb,pinmux-ids = <0x10cf>;
			};

			pwm8_pins_a: pwm8@0 {
				reg = <0>;
				amb,pinmux-ids = <0x2016>;
			};

			pwm8_pins_b: pwm8@1 {
				reg = <1>;
				amb,pinmux-ids = <0x10d0>;
			};

			pwm9_pins_a: pwm9@0 {
				reg = <0>;
				amb,pinmux-ids = <0x2017>;
			};

			pwm9_pins_b: pwm9@1 {
				reg = <1>;
				amb,pinmux-ids = <0x10d1>;
			};

			pwm10_pins_a: pwm10@0 {
				reg = <0>;
				amb,pinmux-ids = <0x2018>;
			};

			pwm10_pins_b: pwm10@1 {
				reg = <1>;
				amb,pinmux-ids = <0x10d2>;
			};

			pwm11_pins_a: pwm11@0 {
				reg = <0>;
				amb,pinmux-ids = <0x2019>;
			};

			pwm11_pins_b: pwm11@1 {
				reg = <1>;
				amb,pinmux-ids = <0x10d3>;
			};

			spi0_pins: spi0@0 {
				reg = <0>;
				amb,pinmux-ids = <0x1002 0x1003 0x1004>;
			};

			spi1_pins: spi1@0 {
				reg = <0>;
				amb,pinmux-ids = <0x1007 0x1008 0x1009>;
			};

			spi2_pins_a: spi2@0 {
				reg = <0>;
				amb,pinmux-ids = <0x100b 0x100c 0x100d>;
			};

			spi2_pins_b: spi2@1 {
				reg = <1>;
				amb,pinmux-ids = <0x405b 0x405c 0x405d>;
			};

			spi3_pins_a: spi3@0 {
				reg = <0>;
				amb,pinmux-ids = <0x200f 0x2010 0x2011>;
			};

			spi3_pins_b: spi3@1 {
				reg = <1>;
				amb,pinmux-ids = <0x303f 0x3040 0x3041>;
			};

			spi3_pins_c: spi3@2 {
				reg = <2>;
				amb,pinmux-ids = <0x306a 0x306b 0x306c>;
			};

			spi4_pins_a: spi4@0 {
				reg = <0>;
				amb,pinmux-ids = <0x3043 0x3046 0x3047>;
			};

			spi4_pins_b: spi4@1 {
				reg = <1>;
				amb,pinmux-ids = <0x305b 0x305c 0x305d>;
			};

			spi4_pins_c: spi4@2 {
				reg = <2>;
				amb,pinmux-ids = <0x50cf 0x50d0 0x50d1>;
			};

			spi5_pins_a: spi5@0 {
				reg = <0>;
				amb,pinmux-ids = <0x304d 0x304f 0x3050>;
			};

			spi5_pins_b: spi5@1 {
				reg = <1>;
				amb,pinmux-ids = <0x305f 0x3061 0x3062>;
			};

			spi5_pins_c: spi5@2 {
				reg = <2>;
				amb,pinmux-ids = <0x40a7 0x40a9 0x40aa>;
			};

			spi_slave_pins: spi_slave@0 {
				reg = <0>;
				amb,pinmux-ids = <0x100f 0x1010 0x1011 0x1012>;
			};
		};
	};

	ca78ae_scratchpad@0xfff0200000 {
		compatible = "simple-bus";
		#address-cells = <1>;
		#size-cells = <1>;
		reg = <0xff 0xf0200000 0x0 0x00010000>;
		ranges = <0xf0200000 0xff 0xf0200000 0x00010000>;

		ca78ae_scratchpad_syscon: ca78ae_scratchpad_syscon@f0200000 {
			compatible = "ambarella,ca78ae-scratchpad", "syscon";
			reg = <0xf0200000 0x10000>;
		};
	};

	hsm {
		compatible = "ambarella,hsm";
		#address-cells = <1>;
		#size-cells = <1>;
		interrupts = <0 28 0x1>, <0 29 0x1>, <0 30 0x1>;
		interrupt-names = "dram_comm0", "dram_comm1", "dram_comm2";
		domain = "SAFETY";
		scr-regmap = <&ca78ae_scratchpad_syscon>;
	};

	ahb@ffe0000000 {
		compatible = "simple-bus";
		#address-cells = <1>;
		#size-cells = <1>;
		reg = <0xff 0xe0000000 0x0 0x01000000>;
		ranges = <0xe0000000 0xff 0xe0000000 0x01000000>;

		n_scratchpad_syscon: scratchpad_syscon@e0024000 {
			compatible = "ambarella,nsec-scratchpad", "syscon";
			reg = <0xe0024000 0x1000>;
		};

		/* note: use s_scratchpad@xxx for unique naming */
		s_scratchpad: s_scratchpad@e002e000 {
			compatible = "ambarella,sec-scratchpad", "syscon";
			reg = <0xe002e000 0x1000>;
			amb,secure-ctrl-bit = <31>;
		};

		cpuid_syscon: cpuid@e0000000 {
			compatible = "ambarella,cpuid", "syscon";
			reg = <0xe0000000 0x1000>;
		};

		pcie0_phyrst: pcie0-phyrst {
			compatible = "ambarella,pcie-phyrst";
			#reset-cells = <1>;
			amb,scr-regmap = <&n_scratchpad_syscon 0x180 0x190 0x194>;
			amb,pcie-controller = <&pciec0>;
			amb,pcie-phy-id = <0>;
		};

		pcie1_phyrst: pcie1-phyrst {
			compatible = "ambarella,pcie-phyrst";
			#reset-cells = <1>;
			amb,scr-regmap = <&n_scratchpad_syscon 0x184 0x190 0x198>;
			amb,pcie-controller = <&pciec1>;
			amb,pcie-phy-id = <1>;
			status = "disabled";
		};

		pcie2_phyrst: pcie2-phyrst {
			compatible = "ambarella,pcie-phyrst";
			#reset-cells = <1>;
			amb,scr-regmap = <&n_scratchpad_syscon 0x188 0x190 0x19c>;
			amb,pcie-controller = <&pciec2>;
			amb,pcie-phy-id = <2>;
			status = "okay";
		};

		usb32_phyrst: usb32-phyrst {
			compatible = "ambarella,usb32-phyrst";
			#reset-cells = <1>;
			amb,scr-regmap = <&n_scratchpad_syscon 0x154 0x174 0x16c>;
		};

		spinor0: spinor@e0001000 {
			compatible = "ambarella,spinor";
			reg = <0xe0001000 0x1000>;
			interrupts = <0 134 0x4>;
			pinctrl-names = "default";
			pinctrl-0 = <&spinor_pins>;
			clocks = <&gclk_ssi3>;
			dmas = <&dma0 5>, <&dma0 6>;
			dma-names = "tx", "rx";
			max-frequency = <50000000>;
			status = "disabled";
		};

		nand0: nand@e0002000 {
			compatible = "ambarella,nand";
			reg = <0xe0002000 0x1000>;
			interrupts = <0 132 0x4>;
			pinctrl-names = "default";
			pinctrl-0 = <&snand_pins>;
			clocks = <&gclk_nand>;
			nand-on-flash-bbt;
			/* amb,soft-ecc = <6>; */
		};

		udc0: udc@e0006000 {
			compatible = "ambarella,udc";
			reg = <0xe0006000 0x2000>;
			interrupts = <0 126 0x4>;
			amb,scr-regmap = <&n_scratchpad_syscon 25>;
			amb,usbphy = <&usbphy>;
		};

		dma0: dma@e0020000 {
			compatible = "ambarella,dma";
			reg = <0xe0020000 0x1000>;
			interrupts = <0 146 0x4>;
			#dma-cells = <1>;
			dma-channels = <8>;
			dma-requests = <29>;
			amb,scr-regmap = <&s_scratchpad 0x2c 0xc4>;
		};

		dma1: dma@e0021000 {
			compatible = "ambarella,dma";
			reg = <0xe0021000 0x1000>;
			interrupts = <0 147 0x4>;
			#dma-cells = <1>;
			dma-channels = <8>;
			dma-requests = <29>;
			amb,scr-regmap = <&s_scratchpad 0xc8 0xcc>;
		};

		dma2: dma@e0029000 {
			compatible = "ambarella,dma";
			reg = <0xe0029000 0x1000>;
			interrupts = <0 148 0x4>;
			#dma-cells = <1>;
			dma-channels = <8>;
			dma-requests = <29>;
			amb,scr-regmap = <&s_scratchpad 0x24 0x28>;
		};

		gdma0: gdma@e000b000 {
			compatible = "ambarella,gdma";
			reg = <0xe000b000 0x1000>;
			interrupts = <0 103 0x1>;
		};

		gdma1: gdma@e001b000 {
			compatible = "ambarella,gdma";
			reg = <0xe001b000 0x1000>;
			interrupts = <0 104 0x1>;
		};

		gdma2: gdma@e001e000 {
			compatible = "ambarella,gdma";
			reg = <0xe001e000 0x1000>;
			interrupts = <0 105 0x1>;
		};

		gdma3: gdma@e001f000 {
			compatible = "ambarella,gdma";
			reg = <0xe001f000 0x1000>;
			interrupts = <0 106 0x1>;
		};

		i2s0: i2s@e001c000 {
			compatible = "ambarella,i2s";
			#sound-dai-cells = <0>;
			reg = <0xe001c000 0x1000>;
			pinctrl-names = "default";
			pinctrl-0 = <&i2s0_pins>;
			clocks = <&gclk_audio>;
			amb,i2s-channels = <2>;
			amb,default-mclk = <12288000>;
			dmas = <&dma0 21>, <&dma0 22>;
			dma-names = "tx", "rx";
			amb,ws-set;
			amb,clk-au-enable;
			amb,scr-regmap = <&n_scratchpad_syscon 0x110>;
			status = "disabled";
		};

		i2s1: i2s@e001d000 {
			compatible = "ambarella,i2s";
			#sound-dai-cells = <0>;
			reg = <0xe001d000 0x1000>;
			pinctrl-names = "default";
			pinctrl-0 = <&i2s1_pins>;
			clocks = <&gclk_audio2>;
			amb,i2s-channels = <2>;
			amb,default-mclk = <12288000>;
			dmas = <&dma0 23>, <&dma0 24>;
			dma-names = "tx", "rx";
			amb,ws-set;
			amb,clk-au-enable;
			amb,scr-regmap = <&n_scratchpad_syscon 0x110>;
			status = "disabled";
		};

		stmmac_axi_setup: stmmac-axi-config {
			/* enable IS_ENABLED(CONFIG_ARCH_DMA_ADDR_T_64BIT) to enable 40bits dma
			   descriptor must be within 4GB.  buffer-addr can be 40bit
			 */
			snps,wr_osr_lmt = <0x4>;	/* cv3:max 8 Ref DMA_SysBus_Mode */
			snps,rd_osr_lmt = <0x4>;	/* cv3:max 8 Ref DMA_SysBus_Mode */
			snps,blen = <256 128 64 32 0 0 0>;	/* when FB=0,last 3 item has no mean */
		};

		mtl_rx_setup: rx-queues-config {
			snps,rx-queues-to-use = <1>;
			snps,rx-sched-sp;
			queue0 {
				snps,dcb-algorithm;		/* data-center-bridge */
				snps,map-to-dma-channel = <0x0>;
				snps,priority = <0x0>;
			};

			/*
			queue1 {
				snps,dcb-algorithm;
				snps,map-to-dma-channel = <0x1>;
				snps,priority = <0x1>;
			};*/
		};

		mtl_tx_setup: tx-queues-config {
			snps,tx-queues-to-use = <1>;
			snps,tx-sched-wrr;			/* schedule-algo wrr */
			queue0 {
				snps,dcb-algorithm;
				snps,weight = <0x10>;
				snps,priority = <0x0>;
			};

			/*
			queue1 {
				snps,dcb-algorithm;
				snps,weight = <0x20>;
				snps,priority = <0x1>;
			};
			*/
		};

		/* mac version 5.20  */
		mac0: ethernet@e000e000 {
			compatible = "ambarella-dwmac-eqos","snps,dwmac-5.10a","snps,dwmac";
			#address-cells = <1>;
			#size-cells = <0>;
			reg = <0xe000e000 0x2000>;
			interrupt-parent = <&gic>;
			interrupts = <0 96 0x4>,<0 95 0x4>,<0 91 0x4>;
			interrupt-names="macirq","eth_wake_irq","eth_lpi";

			snps,multicast-filter-bins = <64>;
			snps,perfect-filter-entries = <3>;
			rx-fifo-depth = <8192>;
			tx-fifo-depth = <16384>;
			clocks = <&pll_out_enet>, <&osc>;	/* ptp_ref from ??? */
			clock-names = "stmmaceth","ptp_ref";
			max-speed = <1000>;			/* max_1000M */

			snps,tso;
			snps,pbl=<32>;
			snps,no-pbl-x8;
			snps,fixed-burst;
			/*
			 * normal: snps,force_sf_dma_mode;
			 * max-frame-size = <1500>; mtu=1500;
			 * jumbo : snps,force_thresh_dma_mode
			*/
			/*snps,force_sf_dma_mode;*/
			snps,axi-config = <&stmmac_axi_setup>;
			snps,mtl-rx-config = <&mtl_rx_setup>;
			snps,mtl-tx-config = <&mtl_tx_setup>;

			amb,ahb-12mhz-div = <5>;
			amb,tx-clk-invert;
			amb,rct-regmap = <&rct_syscon>;
			amb,scr-regmap = <&n_scratchpad_syscon>;
			amb,dma-eame;	/* must ENABLED(CONFIG_ARCH_DMA_ADDR_T_64BIT) to use 40bits dma */
			pinctrl-names = "default";
			pinctrl-0 = <&rgmii0_pins &enet_ext_osc_clk &enet_2nd_ref_clk_c>;
			snps,ps-speed=<1000>;	/* RGMII_SPeed:10/100/1000 base_on enet_ext_osc_clk(2.5M/25M/125M) */
			status = "disabled";
		};

		mac1: ethernet@e0022000 {
			compatible = "ambarella-dwmac-eqos","snps,dwmac-5.10a","snps,dwmac";
			#address-cells = <1>;
			#size-cells = <0>;
			reg = <0xe0022000 0x2000>;
			interrupts = <0 98 0x4>,<0 97 0x4>,<0 92 0x4>;
			interrupt-names="macirq","eth_wake_irq","eth_lpi";
			snps,multicast-filter-bins = <64>;
			snps,perfect-filter-entries = <3>;
			rx-fifo-depth = <8192>;
			tx-fifo-depth = <16384>;
			clocks = <&pll_out_enet>, <&osc>;
			clock-names = "stmmaceth","ptp_ref";
			max-speed = <1000>;

			snps,tso;
			snps,pbl=<32>;
			snps,no-pbl-x8;
			snps,fixed-burst;
			/*snps,force_sf_dma_mode;*/

			snps,axi-config = <&stmmac_axi_setup>;
			snps,mtl-rx-config = <&mtl_rx_setup>;
			snps,mtl-tx-config = <&mtl_tx_setup>;
			amb,ahb-12mhz-div = <5>;
			amb,tx-clk-invert;
			amb,rct-regmap = <&rct_syscon>;
			amb,scr-regmap = <&n_scratchpad_syscon>;
			amb,dma-eame;
			pinctrl-names = "default";
			pinctrl-0 = <&rgmii1_pins>;
			snps,ps-speed=<1000>;
			status = "disabled";
		};

		mac2: ethernet@e002a000 {
			compatible = "ambarella-dwmac-eqos","snps,dwmac-5.10a","snps,dwmac";
			#address-cells = <1>;
			#size-cells = <0>;
			reg = <0xe002a000 0x2000>;
			interrupts = <0 100 0x4>,<0 99 0x4>,<0 93 0x4>;
			interrupt-names="macirq","eth_wake_irq","eth_lpi";
			snps,multicast-filter-bins = <64>;
			snps,perfect-filter-entries = <3>;
			rx-fifo-depth = <8192>;
			tx-fifo-depth = <16384>;
			clocks = <&pll_out_enet>, <&osc>;
			clock-names = "stmmaceth","ptp_ref";
			max-speed = <1000>;

			snps,tso;
			snps,pbl=<32>;
			snps,no-pbl-x8;
			snps,fixed-burst;
			/*snps,force_sf_dma_mode;*/

			snps,axi-config = <&stmmac_axi_setup>;
			snps,mtl-rx-config = <&mtl_rx_setup>;
			snps,mtl-tx-config = <&mtl_tx_setup>;
			amb,ahb-12mhz-div = <5>;
			amb,tx-clk-invert;
			amb,rct-regmap = <&rct_syscon>;
			amb,scr-regmap = <&n_scratchpad_syscon>;
			amb,dma-eame;
			pinctrl-names = "default";
			pinctrl-0 = <&rgmii2_pins>;
			snps,ps-speed=<1000>;
			status = "disabled";
		};

		mac3: ethernet@e002c000 {
			compatible = "ambarella-dwmac-eqos","snps,dwmac-5.10a","snps,dwmac";
			#address-cells = <1>;
			#size-cells = <0>;
			reg = <0xe002c000 0x2000>;
			interrupts = <0 102 0x4>,<0 101 0x4>,<0 94 0x4>;
			interrupt-names="macirq","eth_wake_irq","eth_lpi";
			snps,multicast-filter-bins = <64>;
			snps,perfect-filter-entries = <3>;
			rx-fifo-depth = <8192>;
			tx-fifo-depth = <16384>;
			clocks = <&pll_out_enet>, <&osc>;
			clock-names = "stmmaceth","ptp_ref";
			max-speed = <1000>;

			snps,tso;
			snps,pbl=<32>;
			snps,no-pbl-x8;
			snps,fixed-burst;
			/*snps,force_sf_dma_mode;*/

			snps,axi-config = <&stmmac_axi_setup>;
			snps,mtl-rx-config = <&mtl_rx_setup>;
			snps,mtl-tx-config = <&mtl_tx_setup>;
			amb,ahb-12mhz-div = <5>;
			amb,tx-clk-invert;
			amb,rct-regmap = <&rct_syscon>;
			amb,scr-regmap = <&n_scratchpad_syscon>;
			amb,dma-eame;
			pinctrl-names = "default";
			pinctrl-0 = <&rgmii3_pins>;
			snps,ps-speed=<1000>;
			status = "disabled";
		};

		spi0: spi@e0011000 {
			compatible = "ambarella,spi";
			#address-cells = <1>;
			#size-cells = <0>;
			reg = <0xe0011000 0x1000>;
			interrupts = <0 135 0x4>;
			pinctrl-names = "default";
			pinctrl-0 = <&spi0_pins>;
			clocks = <&gclk_ssi>;
			/* amb,dma-used; */
			dmas = <&dma0 1>, <&dma0 2>;
			dma-names = "tx", "rx";
			status = "disabled";
		};

		spi1: spi@e0012000 {
			compatible = "ambarella,spi";
			#address-cells = <1>;
			#size-cells = <0>;
			reg = <0xe0012000 0x1000>;
			interrupts = <0 136 0x4>;
			pinctrl-names = "default";
			pinctrl-0 = <&spi1_pins>;
			clocks = <&gclk_ssi>;
			/* amb,dma-used; */
			dmas = <&dma0 3>, <&dma0 4>;
			dma-names = "tx", "rx";
			status = "disabled";
		};

		spi2: spi@e0013000 {
			compatible = "ambarella,spi";
			#address-cells = <1>;
			#size-cells = <0>;
			reg = <0xe0013000 0x1000>;
			interrupts = <0 137 0x4>;
			pinctrl-names = "default";
			pinctrl-0 = <&spi2_pins_a>;
			clocks = <&gclk_ssi>;
			/* amb,dma-used; */
			dmas = <&dma1 17>, <&dma1 18>;
			dma-names = "tx", "rx";
			status = "disabled";
		};

		spi3: spi@e0014000 {
			compatible = "ambarella,spi";
			#address-cells = <1>;
			#size-cells = <0>;
			reg = <0xe0014000 0x1000>;
			interrupts = <0 138 0x4>;
			pinctrl-names = "default";
			pinctrl-0 = <&spi3_pins_c>;
			clocks = <&gclk_ssi>;
			/* amb,dma-used; */
			dmas = <&dma1 19>, <&dma1 20>;
			dma-names = "tx", "rx";
			status = "disabled";
		};

		spi4: spi@e0025000 {
			compatible = "ambarella,spi";
			#address-cells = <1>;
			#size-cells = <0>;
			reg = <0xe0025000 0x1000>;
			interrupts = <0 139 0x4>;
			pinctrl-names = "default";
			pinctrl-0 = <&spi4_pins_b>;
			clocks = <&gclk_ssi>;
			/* amb,dma-used; */
			dmas = <&dma1 25>, <&dma1 26>;
			dma-names = "tx", "rx";
			status = "disabled";
		};

		spi5: spi@e0026000 {
			compatible = "ambarella,spi";
			#address-cells = <1>;
			#size-cells = <0>;
			reg = <0xe0026000 0x1000>;
			interrupts = <0 140 0x4>;
			pinctrl-names = "default";
			pinctrl-0 = <&spi5_pins_c>;
			clocks = <&gclk_ssi>;
			/* amb,dma-used; */
			dmas = <&dma1 27>, <&dma1 28>;
			dma-names = "tx", "rx";
			status = "disabled";
		};

		spi_slave@e0010000 {
			compatible = "ambarella,spi-slave";
			reg = <0xe0010000 0x1000>;
			interrupts = <0 141 0x4>;
			pinctrl-names = "default";
			pinctrl-0 = <&spi_slave_pins>;
			clocks = <&gclk_ssi2>;
			dmas = <&dma1 7>, <&dma1 8>;
			dma-names = "tx", "rx";
			amb,dma-buf-size = <2048>;
			status = "disabled";
		};

		dmic: dmic@e0015000 {
			compatible = "ambarella,dmic";
			#sound-dai-cells = <0>;
			pinctrl-names = "default";
			pinctrl-0 = <&dmic0_pins>;
			reg = <0xe0015000 0x1000>;
			amb,scr-regmap = <&n_scratchpad_syscon>;
			amb,custom-iir;
			status = "disabled";
		};

		hdmi: hdmi@e0016000 {
			compatible = "ambarella,hdmi";
			reg = <0xe0016000 0x1000>;
			interrupts = <0 127 0x4>;
			interrupt-names = "hdmi";
			vout_id = <2>;
			amb,hdmi-version = <20>;
			amb,phy-regmap = <&rct_syscon 0x7f0 0x7c0 0x7c4>;
			/* phy val : <pib pibib pre_emph post_emph termination bias> */
			amb,hdmi-phy-val-version = <1>;
			amb,hdmi-phy-val-low = <1 3 4 6 0 0>;
			amb,hdmi-phy-val-high = <15 3 2 2 31 2>;
		};

		uart1: uart@e0017000 {	/* UART0_AHB */
			compatible = "ambarella,uart";
			reg = <0xe0017000 0x1000>;
			interrupts = <0 128 0x4>;
			pinctrl-names = "default";
			pinctrl-0 = <&uart1_pins_b &uart1_flow_pins_b>;
			clocks = <&gclk_uart1>;
			amb,msr-used;	/* use Modem Status Register */
			amb,txdma-used;
			amb,rxdma-used;
			dmas = <&dma0 9>, <&dma0 10>;
			dma-names = "tx", "rx";
			status = "disabled";
		};

		uart2: uart@e0018000 { 	/* UART1_AHB */
			compatible = "ambarella,uart";
			reg = <0xe0018000 0x1000>;
			interrupts = <0 129 0x4>;
			pinctrl-names = "default";
			pinctrl-0 = <&uart2_pins_a &uart2_flow_pins_a>;
			clocks = <&gclk_uart2>;
			amb,msr-used;	/* use Modem Status Register */
			amb,txdma-used;
			amb,rxdma-used;
			dmas = <&dma1 11>, <&dma1 12>;
			dma-names = "tx", "rx";
			status = "disabled";
		};

		uart3: uart@e0019000 { 	/* UART2_AHB */
			compatible = "ambarella,uart";
			reg = <0xe0019000 0x1000>;
			interrupts = <0 130 0x4>;
			pinctrl-names = "default";
			pinctrl-0 = <&uart3_pins_b &uart3_flow_pins_b>;
			clocks = <&gclk_uart3>;
			amb,msr-used;	/* use Modem Status Register */
			amb,txdma-used;
			amb,rxdma-used;
			dmas = <&dma1 13>, <&dma1 14>;
			dma-names = "tx", "rx";
			status = "disabled";
		};

		uart4: uart@e001a000 { /* UART3_AHB */
			compatible = "ambarella,uart";
			reg = <0xe001a000 0x1000>;
			interrupts = <0 131 0x4>;
			pinctrl-names = "default";
			pinctrl-0 = <&uart4_pins_a &uart4_flow_pins_a>;
			clocks = <&gclk_uart4>;
			amb,msr-used;	/* use Modem Status Register */
			amb,txdma-used;
			amb,rxdma-used;
			dmas = <&dma1 15>, <&dma1 16>;
			dma-names = "tx", "rx";
			status = "disabled";
		};

		can0: can@e0027000 {
			compatible = "ambarella,can";
			reg = <0xe0027000 0x1000>;
			interrupts = <0 107 0x4>;
			interrupt-names = "canc0";
			pinctrl-names = "default";
			pinctrl-0 = <&can0_pins>;
			clocks = <&gclk_can>;
			status = "disabled";
		};

		can1: can@e0028000 {
			compatible = "ambarella,can";
			reg = <0xe0028000 0x1000>;
			interrupts = <0 108 0x4>;
			interrupt-names = "canc0";
			pinctrl-names = "default";
			pinctrl-0 = <&can1_pins>;
			clocks = <&gclk_can>;
			status = "disabled";
		};

		rtc0: rtc@e002e000 {
			compatible = "ambarella,rtc";
			reg = <0xe002e000 0x100>;
			amb,secure-ctrl-bit = <31>;
			/*sdk8: do not disable rtc*/
			/*status = "disabled";*/
		};

		rng0: rng@e002e000 {
			compatible = "ambarella,hw-rng";
			reg = <0xe002e000 0x14>;
			amb,rct-regmap = <&rct_syscon>;
			amb,secure-ctrl-bit = <31>;
		};
	};

	debug-bus@ffed000000 {
		compatible = "simple-bus";
		#address-cells = <1>;
		#size-cells = <1>;
		reg = <0xff 0xed000000 0x0 0x1000000>;
		ranges = <0xed000000 0xff 0xed000000 0x1000000>;

		ddrh_syscon: ddrh_syscon@ed190000 {
			compatible = "ambarella,ddrh", "syscon";
			reg = <0xed190000 0x1000>;
			amb,secure-ctrl-bit = <87>;
		};

	    ddrh0: ddrh0@ed190000 {
		    reg = <0xed190000 0x1000>;
        };
	    ddrh1: ddrh1@ed1a0000 {
		    reg = <0xed1a0000 0x1000>;
        };
	    ddrh2: ddrh2@ed230000 {
		    reg = <0xed230000 0x1000>;
        };
	    ddrh3: ddrh3@ed240000 {
		    reg = <0xed240000 0x1000>;
        };
	    ddrh4: ddrh4@ed250000 {
		    reg = <0xed250000 0x1000>;
        };
	    ddrh5: ddrh5@ed260000 {
		    reg = <0xed260000 0x1000>;
        };
	    ddrh6: ddrh6@ed270000 {
		    reg = <0xed270000 0x1000>;
        };
	    ddrh7: ddrh7@ed280000 {
		    reg = <0xed280000 0x1000>;
        };

		dbse: dbse@ed1f0000 {
			reg = <0xed1f0000 0x1000>;
        };

		rct_syscon: rct_syscon@ed080000 {
			compatible = "ambarella,rct", "syscon";
			reg = <0xed080000 0x1000>;
			amb,secure-ctrl-bit = <68>;
/*
			amb,secure-reg-ro = <0xed080000 0x008>, <0xed080034 0x004>,
					    <0xed08008c 0x004>, <0xed0800dc 0x010>,
					    <0xed080100 0x01c>, <0xed080148 0x004>,
					    <0xed080174 0x00c>, <0xed0801f4 0x004>,
					    <0xed080224 0x008>, <0xed080264 0x014>,
					    <0xed0802dc 0x00c>, <0xed0803f8 0x008>,
					    <0xed0804f8 0x004>, <0xed0806e4 0x014>,
					    <0xed08070c 0x008>, <0xed080794 0x004>;
*/
		};

		/* TW ---start */
		vout: vout@ed0a0000 {
			compatible = "ambarella,vout";
			reg = <0xed0a0000 0x1000>;
		};

		vout_tvenc: vout_tvenc@ed0a0000 {
			compatible = "ambarella,vout_tvenc";
			reg = <0xed0a0000 0x200>;
		};

		vout_display0: vout_display0@ed0a0300 {
			compatible = "ambarella,vout_display0";
			reg = <0xed0a0300 0x200>;
		};

		vout_display1: vout_display1@ed0a0600 {
			compatible = "ambarella,vout_display1";
			reg = <0xed0a0600 0x200>;
		};

		vout_display2: vout_display2@ed0a0c00 {
			compatible = "ambarella,vout_display2";
			reg = <0xed0a0c00 0x200>;
		};

		vout_top: vout_top@ed0a0a00 {
			compatible = "ambarella,vout_top";
			reg = <0xed0a0a00 0x100>;
		};

		vout_mipi_dsi_cmd0: vout_mipi_dsi_cmd0@ed0a0b00 {
			compatible = "ambarella,vout_mipi_dsi_cmd0";
			reg = <0xed0a0b00 0x100>;
		};

		vout_mipi_dsi_cmd1: vout_mipi_dsi_cmd1@ed0a0e00 {
			compatible = "ambarella,vout_mipi_dsi_cmd1";
			reg = <0xed0a0e00 0x100>;
		};
		/* TW +++ end */

		/* TW --- start */
		idsp_controller: idsp_controller@ed1e8000 {
			compatible = "ambarella,idsp-controller";
			reg = <0xed1e8000 0x8000>;
		};

		idsp_vin_global: idsp_vin_global@ed1e0800 {
			compatible = "ambarella,idsp-vin-global";
			reg = <0xed1e0800 0x4>;
		};

		idsp_vin_main: idsp_vin_main@ed1e0000 {
			compatible = "ambarella,idsp-vin-main";
			reg = <0xed1e0000 0x204>;
		};

		idsp_vin_msync: idsp_vin_msync@ed1e0400 {
			compatible = "ambarella,idsp-vin-msync";
			reg = <0xed1e0400 0x24>;
		};

		mipi_phy: mipi_phy@ed200000 {
			compatible = "ambarella,mipi-phy";
			reg = <0xed200000 0x13c>;
		};

		idsp1_controller: idsp1_controller@ed1b8000 {
			compatible = "ambarella,idsp1-controller";
			reg = <0xed1b8000 0x8000>;
		};

		idsp1_vin_global: idsp1_vin_global@ed1b0800 {
			compatible = "ambarella,idsp1-vin-global";
			reg = <0xed1b0800 0x4>;
		};

		idsp1_vin_main: idsp1_vin_main@ed1b0000 {
			compatible = "ambarella,idsp1-vin-main";
			reg = <0xed1b0000 0x204>;
		};

		idsp1_vin_msync: idsp1_vin_msync@ed1b0400 {
			compatible = "ambarella,idsp1-vin-msync";
			reg = <0xed1b0400 0x24>;
		};

		mipi1_phy: mipi1_phy@ed090000 {
			compatible = "ambarella,mipi1-phy";
			reg = <0xed090000 0x13c>;
		};
		/* TW +++ end */
		usbphy: usbphy {
			compatible = "ambarella,usbphy";
			amb,ana-regmap = <&rct_syscon 0x050>;
			amb,own-regmap = <&rct_syscon 0x2c0>;		/* TODO: no such register in RCT */
			amb,phy-regmap = <&n_scratchpad_syscon 0x118>;
			amb,pol-regmap = <&n_scratchpad_syscon 0x060>;	/* TODO: polarity is remvoed in CV5 */
			amb,host-phy-num = <1>;
			amb,ocp-polarity = <0>;
		};

		reboot {
			compatible = "ambarella,reboot";
			amb,rct-regmap = <&rct_syscon>;
		};
	};

	bogus_bus {
		compatible = "simple-bus";
		#address-cells = <1>;
		#size-cells = <0>;

		dummycodec: codec@0 {
			compatible = "ambarella,dummycodec";
			reg = <0>;
		};

		framebuffer0: framebuffer@0 {
			compatible = "ambarella,fb";
			reg = <0>;
			amb,vout-id = <0>;
			amb,format = "rgb565";
			status = "disabled";
		};

		framebuffer1: framebuffer@1 {
			compatible = "ambarella,fb";
			reg = <1>;
			amb,vout-id = <1>;
			amb,format = "rgb565";
			status = "disabled";
		};

		framebuffer2: framebuffer@2 {
			compatible = "ambarella,fb";
			reg = <2>;
			amb,vout-id = <2>;
			amb,format = "rgb565";
			status = "disabled";
		};
	};

	clocks {
		compatible = "ambarella,clkpll-v1";
		#address-cells = <2>;
		#size-cells = <1>;

		/*
		 * This is a dummy clock, to be used as placeholder on other
		 * mux clocks when corresponding bits in register don't
		 * represent real parent clock.
		 */
		gclk_dummy: gclk_dummy {
			#clock-cells = <0>;
			compatible = "fixed-clock";
			clock-frequency = <0>;
		};

		/*
		 * Fixed 24MHz oscillator inputs to SoC
		 */
		osc: oscillator {
			compatible = "fixed-clock";
			#clock-cells = <0>;
			clock-frequency = <24000000>;
			clock-output-names = "osc";
		};

		gclk_core: gclk-core {
			#clock-cells = <0>;
			compatible = "ambarella,pll-clock";
			clocks = <&osc>;
			clock-output-names = "gclk_core";
			amb,clk-regmap = <&rct_syscon 0x000 0x004 0x100 0x104 0x000 0x000>;
			amb,obsv-id = <0x00>;
		};

		gclk_ahb: gclk-ahb {
			#clock-cells = <0>;
			compatible = "ambarella,fixed-factor-clock";
			clocks = <&gclk_core>;
			clock-output-names = "gclk_ahb";
			clock-mult = <1>;
			clock-div = <2>;
		};

		gclk_apb: gclk-apb {
			#clock-cells = <0>;
			compatible = "ambarella,fixed-factor-clock";
			clocks = <&gclk_core>;
			clock-output-names = "gclk_apb";
			clock-mult = <1>;
			clock-div = <4>;
		};

		gclk_ddr0: gclk-ddr0 {
			#clock-cells = <0>;
			compatible = "ambarella,pll-clock";
			clocks = <&osc>;
			clock-output-names = "gclk_ddr0";
			amb,clk-regmap = <&ddrh_syscon 0x000 0x004 0x008 0x00c 0x000 0x000>;
			amb,fix-divider = <2>;
			amb,obsv-id = <0x02>;
		};

		gclk_cortex: gclk-cortex {
			#clock-cells = <0>;
			compatible = "ambarella,pll-clock";
			clocks = <&osc>;
			clock-output-names = "gclk_cortex";
			amb,clk-regmap = <&rct_syscon 0x264 0x268 0x26c 0x270 0x000 0x000>;
			amb,obsv-id = <0x3a>;
		};

		gclk_dsu: gclk-dsu {
			#clock-cells = <0>;
			compatible = "ambarella,pll-clock";
			clocks = <&osc>;
			clock-output-names = "gclk_dsu";
			amb,clk-regmap = <&rct_syscon 0x814 0x818 0x81c 0x820 0x000 0x000>;
			amb,obsv-id = <0x03>;
		};

		gclk_axi: gclk-axi {
			#clock-cells = <0>;
			compatible = "ambarella,fixed-factor-clock";
			clocks = <&gclk_dsu>;
			clock-output-names = "gclk_axi";
			clock-mult = <1>;
			clock-div = <2>;
		};

		gclk_gpu: gclk-gpu {
			#clock-cells = <0>;
			compatible = "ambarella,pll-clock";
			clocks = <&osc>;
			clock-output-names = "gclk_gpu";
			amb,clk-regmap = <&rct_syscon 0x828 0x82c 0x830 0x834 0x000 0x000>;
			amb,obsv-id = <0x2b>;
		};

		gclk_hsm: gclk-hsm {
			#clock-cells = <0>;
			compatible = "ambarella,pll-clock";
			clocks = <&osc>;
			clock-output-names = "gclk_hsm";
			amb,clk-regmap = <&rct_syscon 0x83c 0x840 0x844 0x848 0x000 0x000>;
			amb,obsv-id = <0x2a>;
		};

		gclk_fma: gclk-fma {
			#clock-cells = <0>;
			compatible = "ambarella,pll-clock";
			clocks = <&osc>;
			clock-output-names = "gclk_fma";
			amb,clk-regmap = <&rct_syscon 0x850 0x854 0x858 0x85c 0x000 0x000>;
			amb,obsv-id = <0x28>;
		};

		gclk_core_dsp: gclk-core-dsp {
			#clock-cells = <0>;
			compatible = "ambarella,pll-clock";
			clocks = <&osc>;
			clock-output-names = "gclk_core_dsp";
			amb,clk-regmap = <&rct_syscon 0x864 0x868 0x86c 0x870 0x000 0x000>;
		};

		gclk_vdsp: gclk-vdsp {
			#clock-cells = <0>;
			compatible = "ambarella,pll-clock";
			clocks = <&osc>;
			clock-output-names = "gclk_vdsp";
			amb,clk-regmap = <&rct_syscon 0x8d4 0x8d8 0x8dc 0x8e0 0x000 0x000>;
			amb,obsv-id = <0x04>;
		};

		gclk_idsp: gclk-idsp {
			#clock-cells = <0>;
			compatible = "ambarella,pll-clock";
			clocks = <&osc>;
			clock-output-names = "gclk_idsp";
			amb,clk-regmap = <&rct_syscon 0x0e4 0x0e8 0x108 0x10c 0x000 0x000>;
			amb,obsv-id = <0x01>;
		};

		gclk_idspv: gclk-idspv {
			#clock-cells = <0>;
			compatible = "ambarella,pll-clock";
			clocks = <&osc>;
			clock-output-names = "gclk_idspv";
			amb,clk-regmap = <&rct_syscon 0x7d8 0x7dc 0x7e0 0x7e4 0x000 0x000>;
			amb,obsv-id = <0x05>;
		};

		gclk_nvp: gclk-nvp {
			#clock-cells = <0>;
			compatible = "ambarella,pll-clock";
			clocks = <&osc>;
			clock-output-names = "gclk_nvp";
			amb,clk-regmap = <&rct_syscon 0x878 0x87c 0x880 0x884 0x000 0x000>;
			amb,obsv-id = <0x20>;
		};

		gclk_gvp: gclk-gvp {
			#clock-cells = <0>;
			compatible = "ambarella,pll-clock";
			clocks = <&osc>;
			clock-output-names = "gclk_gvp";
			amb,clk-regmap = <&rct_syscon 0x88c 0x890 0x894 0x898 0x000 0x000>;
			amb,obsv-id = <0x26>;
		};

		gclk_fex: gclk-fex {
			#clock-cells = <0>;
			compatible = "ambarella,pll-clock";
			clocks = <&osc>;
			clock-output-names = "gclk_fex";
			amb,clk-regmap = <&rct_syscon 0x864 0x868 0x86c 0x870 0x000 0x000>;
			amb,obsv-id = <0x29>;
		};

		gclk_so: gclk-so {
			#clock-cells = <0>;
			compatible = "ambarella,pll-clock";
			clocks = <&osc>;
			clock-output-names = "gclk_so";
			assigned-clocks = <&gclk_so>;
			assigned-clock-rates = <24000000>;
			amb,clk-regmap = <&rct_syscon 0x024 0x028 0x11c 0x120 0x04c 0x030>;
			amb,frac-mode;
			amb,obsv-id = <0x10>;
		};

		gclk_so1: gclk-so1 {
			#clock-cells = <0>;
			compatible = "ambarella,pll-clock";
			clocks = <&osc>;
			clock-output-names = "gclk_so1";
			assigned-clocks = <&gclk_so1>;
			assigned-clock-rates = <24000000>;
			amb,clk-regmap = <&rct_syscon 0x8a0 0x8ac 0x8a4 0x8a8 0x000 0x57c>;
			amb,frac-mode;
			amb,obsv-id = <0x33>;
		};

		gclk_so2: gclk-so2 {
			#clock-cells = <0>;
			compatible = "ambarella,pll-clock";
			clocks = <&osc>;
			clock-output-names = "gclk_so2";
			assigned-clocks = <&gclk_so2>;
			assigned-clock-rates = <24000000>;
			amb,clk-regmap = <&rct_syscon 0x74c 0x758 0x750 0x754 0x000 0x578>;
			amb,frac-mode;
			amb,obsv-id = <0x11>;
		};

		gclk_so3: gclk-so3 {
			#clock-cells = <0>;
			compatible = "ambarella,pll-clock";
			clocks = <&osc>;
			clock-output-names = "gclk_so3";
			assigned-clocks = <&gclk_so3>;
			assigned-clock-rates = <24000000>;
			amb,clk-regmap = <&rct_syscon 0x8b4 0x8c0 0x8b8 0x8bc 0x000 0x580>;
			amb,frac-mode;
			amb,obsv-id = <0x34>;
		};

		pll_out_hdmi: pll-out-hdmi {
			#clock-cells = <0>;
			compatible = "ambarella,pll-clock";
			clocks = <&osc>;
			clock-output-names = "pll_out_hdmi";
			assigned-clocks = <&pll_out_hdmi>;
			assigned-clock-rates = <24000000>;
			amb,clk-regmap = <&rct_syscon 0x1a8 0x1ac 0x1b0 0x1b4 0x000 0x000>;
			amb,frac-mode;
			amb,vco-max-mhz = <6800>;
			amb,ctrl2-val = <0x30520000>;
			amb,ctrl3-val = <0x00088004>;
			amb,obsv-id = <0x08>;
		};

		pll_out_vo2: pll-out-vo2 {
			#clock-cells = <0>;
			compatible = "ambarella,pll-clock";
			clocks = <&osc>;
			clock-output-names = "pll_out_vo2";
			assigned-clocks = <&pll_out_vo2>;
			assigned-clock-rates = <24000000>;
			amb,clk-regmap = <&rct_syscon 0x0c0 0x0c4 0x13c 0x140 0x0c8 0x000>;
			amb,frac-mode;
			amb,vco-max-mhz = <1800>;
			amb,obsv-id = <0x09>;
		};

		gclk_audio: gclk-audio {
			#clock-cells = <0>;
			compatible = "ambarella,pll-clock";
			clocks = <&osc>;
			clock-output-names = "gclk_audio";
			assigned-clocks = <&gclk_audio>;
			assigned-clock-rates = <12288000>;
			amb,clk-regmap = <&rct_syscon 0x054 0x058 0x124 0x12c 0x060 0x05c>;
			amb,frac-mode;
			amb,obsv-id = <0x0b>;
		};

		gclk_audio2: gclk-audio2 {
			#clock-cells = <0>;
			compatible = "ambarella,pll-clock";
			clocks = <&osc>;
			clock-output-names = "gclk_audio2";
			assigned-clocks = <&gclk_audio2>;
			assigned-clock-rates = <12288000>;
			amb,clk-regmap = <&rct_syscon 0x054 0x058 0x124 0x12c 0x060 0x600>;
			amb,frac-mode;
			amb,obsv-id = <0x0b>;
		};

		pll_out_sd: pll-out-sd {
			#clock-cells = <0>;
			compatible = "ambarella,pll-clock";
			clocks = <&osc>;
			clock-output-names = "pll_out_sd";
			amb,clk-regmap = <&rct_syscon 0x4ac 0x4b0 0x4b4 0x4b8 0x000 0x000>;
			amb,obsv-id = <0x0c>;
		};

		gclk_sd0: gclk-sd {
			#clock-cells = <0>;
			compatible = "ambarella,div-clock";
			clocks = <&pll_out_sd>;
			clock-output-names = "gclk_sd0";
			assigned-clock-rates = <240000000>;
			amb,div-regmap = <&rct_syscon 0x00c>;
			amb,div-width = <16>;
			amb,div-shift = <0>;
		};

		gclk_sd1: gclk-sdio0 {
			#clock-cells = <0>;
			compatible = "ambarella,div-clock";
			clocks = <&pll_out_sd>;
			clock-output-names = "gclk_sd1";
			assigned-clock-rates = <240000000>;
			amb,div-regmap = <&rct_syscon 0x430>;
			amb,div-width = <16>;
			amb,div-shift = <0>;
		};

		gclk_sd2: gclk-sdio1 {
			#clock-cells = <0>;
			compatible = "ambarella,div-clock";
			clocks = <&pll_out_sd>;
			clock-output-names = "gclk_sd2";
			amb,div-regmap = <&rct_syscon 0x434>;
			amb,div-width = <16>;
			amb,div-shift = <0>;
		};

		gclk_nand: gclk-nand {
			#clock-cells = <0>;
			compatible = "ambarella,pll-clock";
			clocks = <&osc>;
			clock-output-names = "gclk_nand";
			amb,clk-regmap = <&rct_syscon 0x6f8 0x6fc 0x700 0x704 0x000 0x000>;
			amb,obsv-id = <0x0e>;
		};

		pll_out_enet: pll-out-enet {
			#clock-cells = <0>;
			compatible = "ambarella,pll-clock";
			clocks = <&osc>;
			clock-output-names = "pll_out_enet";
			amb,clk-regmap = <&rct_syscon 0x520 0x524 0x528 0x52c 0x000 0x000>;
			amb,obsv-id = <0x0d>;
		};

		gclk_uart0: gclk-uart0 {
			#clock-cells = <0>;
			compatible = "ambarella,composite-clock";
			clocks = <&osc>, <&gclk_core>, <&pll_out_enet>, <&pll_out_sd>;
			clock-output-names = "gclk_uart0";
			assigned-clocks = <&gclk_uart0>;
			assigned-clock-parents = <&osc>;
			assigned-clock-rates = <24000000>;
			amb,mux-regmap = <&rct_syscon 0x1c8>;
			amb,div-regmap = <&rct_syscon 0x038>;
			amb,div-width = <24>;
			amb,div-shift = <0>;
		};

		gclk_uart1: gclk-uart1 {
			#clock-cells = <0>;
			compatible = "ambarella,composite-clock";
			clocks = <&osc>, <&gclk_core>, <&pll_out_enet>, <&pll_out_sd>;
			clock-output-names = "gclk_uart1";
			assigned-clocks = <&gclk_uart1>;
			assigned-clock-parents = <&osc>;
			assigned-clock-rates = <24000000>;
			amb,mux-regmap = <&rct_syscon 0x72c>;
			amb,div-regmap = <&rct_syscon 0x714>;
			amb,div-width = <24>;
			amb,div-shift = <0>;
		};

		gclk_uart2: gclk-uart2 {
			#clock-cells = <0>;
			compatible = "ambarella,composite-clock";
			clocks = <&osc>, <&gclk_core>, <&pll_out_enet>, <&pll_out_sd>;
			clock-output-names = "gclk_uart2";
			assigned-clocks = <&gclk_uart2>;
			assigned-clock-parents = <&osc>;
			assigned-clock-rates = <24000000>;
			amb,mux-regmap = <&rct_syscon 0x730>;
			amb,div-regmap = <&rct_syscon 0x718>;
			amb,div-width = <24>;
			amb,div-shift = <0>;
		};

		gclk_uart3: gclk-uart3 {
			#clock-cells = <0>;
			compatible = "ambarella,composite-clock";
			clocks = <&osc>, <&gclk_core>, <&pll_out_enet>, <&pll_out_sd>;
			clock-output-names = "gclk_uart3";
			assigned-clocks = <&gclk_uart3>;
			assigned-clock-parents = <&osc>;
			assigned-clock-rates = <24000000>;
			amb,mux-regmap = <&rct_syscon 0x734>;
			amb,div-regmap = <&rct_syscon 0x71c>;
			amb,div-width = <24>;
			amb,div-shift = <0>;
		};

		gclk_uart4: gclk-uart4 {
			#clock-cells = <0>;
			compatible = "ambarella,composite-clock";
			clocks = <&osc>, <&gclk_core>, <&pll_out_enet>, <&pll_out_sd>;
			clock-output-names = "gclk_uart4";
			assigned-clocks = <&gclk_uart4>;
			assigned-clock-parents = <&osc>;
			assigned-clock-rates = <24000000>;
			amb,mux-regmap = <&rct_syscon 0x738>;
			amb,div-regmap = <&rct_syscon 0x720>;
			amb,div-width = <24>;
			amb,div-shift = <0>;
		};

		gclk_ir: gclk-ir {
			#clock-cells = <0>;
			compatible = "ambarella,div-clock";
			clocks = <&osc>;
			clock-output-names = "gclk_ir";
			amb,div-regmap = <&rct_syscon 0x044>;
			amb,div-width = <24>;
			amb,div-shift = <0>;
		};

		gclk_pwm: gclk-pwm {
			#clock-cells = <0>;
			compatible = "ambarella,composite-clock";
			clocks = <&gclk_apb>, <&gclk_hsm>, <&pll_out_enet>, <&osc>;
			clock-output-names = "gclk_pwm";
			assigned-clocks = <&gclk_pwm>;
			assigned-clock-parents = <&pll_out_enet>;
			amb,mux-regmap = <&rct_syscon 0x1c4>;
			amb,div-regmap = <&rct_syscon 0x084>;
			amb,div-width = <24>;
			amb,div-shift = <0>;
		};

		gclk_ssi: gclk-ssi { /* for SSI master */
			#clock-cells = <0>;
			compatible = "ambarella,div-clock";
			clocks = <&gclk_core>;
			clock-output-names = "gclk_ssi";
			assigned-clocks = <&gclk_ssi>;
			assigned-clock-rates = <54000000>;
			amb,div-regmap = <&rct_syscon 0x03c>;
			amb,div-width = <24>;
			amb,div-shift = <0>;
		};

		gclk_ssi2: gclk-ssi2 { /* for SSI slave */
			#clock-cells = <0>;
			compatible = "ambarella,div-clock";
			clocks = <&gclk_core>;
			clock-output-names = "gclk_ssi2";
			amb,div-regmap = <&rct_syscon 0x0ec>;
			amb,div-width = <24>;
			amb,div-shift = <0>;
		};

		gclk_ssi3: gclk-ssi3 { /* for SPINOR */
			#clock-cells = <0>;
			compatible = "ambarella,composite-clock";
			clocks = <&pll_out_enet>, <&gclk_core>, <&gclk_ssi>, <&osc>;
			clock-output-names = "gclk_ssi3";
			amb,mux-regmap = <&rct_syscon 0x51c>;
			amb,div-regmap = <&rct_syscon 0x518>;
			amb,div-width = <24>;
			amb,div-shift = <0>;
		};

		gclk_can: gclk-can {
			#clock-cells = <0>;
			compatible = "ambarella,composite-clock";
			clocks = <&osc>, <&pll_out_enet>, <&gclk_ahb>;
			clock-output-names = "gclk_can";
			assigned-clocks = <&gclk_can>;
			assigned-clock-parents = <&osc>;
			assigned-clock-rates = <24000000>;
			amb,mux-regmap = <&rct_syscon 0x56c>;
			amb,div-regmap = <&rct_syscon 0x570>;
			amb,div-width = <8>;
			amb,div-shift = <0>;
		};

		/* Fixed 100MHz for cdns phy {usb3,pcie,pcie-switch} */
		cdns_phy_refclk: cdns-phy-refclk {
			#clock-cells = <0>;
			compatible = "fixed-clock";
			clock-frequency = <100000000>;
			clock-output-names = "cdns-phy-refclk";
		};
	};

	dsp: dspdrv {
		compatible = "ambarella,dspdrv";
		memory-region = <&dsp_prot_buf>;
		memory-region1 = <&dsp_prot_cache_buf>;
		memory-region2 = <&dsp_bin_buf>;
		memory-region3 = <&dsp_data_buf>;
		interrupts = <0 264 0x1 0 265 0x1 0 267 0x1 0 266 0x1 0 268 0x1 0 262 0x1>;
        interrupt-names = "vdsp0", "vdsp1", "vdsp2", "vdsp3", "vdsp4", "vdsp5";

		/* node for vin0 controller */
		dspvin0 {
			compatible = "ambarella,dspvin";
			interrupts = <0 280 0x1 0 282 0x1 0 279 0x1>;
			interrupt-names = "vin0_arm_sof", "vin0_arm_last_pixel", "vin0_arm_vsync";
		};

		/* node for vin1 controller */
		dspvin1 {
			compatible = "ambarella,dspvin";
			interrupts = <0 284 0x1 0 285 0x1 0 283 0x1>;
			interrupt-names = "vin1_arm_sof", "vin1_arm_last_pixel", "vin1_arm_vsync";
		};

		/* node for vin2 controller */
		dspvin2 {
			compatible = "ambarella,dspvin";
			interrupts = <0 287 0x1 0 288 0x1 0 286 0x1>;
			interrupt-names = "vin2_arm_sof", "vin2_arm_last_pixel", "vin2_arm_vsync";
		};

		/* node for vin3 controller */
		dspvin3 {
			compatible = "ambarella,dspvin";
			interrupts = <0 290 0x1 0 291 0x1 0 289 0x1>;
			interrupt-names = "vin3_arm_sof", "vin3_arm_last_pixel", "vin3_arm_vsync";
		};

		/* node for vin4 controller */
		dspvin4 {
			compatible = "ambarella,dspvin";
			interrupts = <0 293 0x1 0 294 0x1 0 292 0x1>;
			interrupt-names = "vin4_arm_sof", "vin4_arm_last_pixel", "vin4_arm_vsync";
		};

		/* node for vin5 controller */
		dspvin5 {
			compatible = "ambarella,dspvin";
			interrupts = <0 296 0x1 0 297 0x1 0 295 0x1>;
			interrupt-names = "vin5_arm_sof", "vin5_arm_last_pixel", "vin5_arm_vsync";
		};

		/* node for vin6 controller */
		dspvin6 {
			compatible = "ambarella,dspvin";
			interrupts = <0 299 0x1 0 300 0x1 0 298 0x1>;
			interrupt-names = "vin6_arm_sof", "vin6_arm_last_pixel", "vin6_arm_vsync";
		};

		/* node for vin7 controller */
		dspvin7 {
			compatible = "ambarella,dspvin";
			interrupts = <0 302 0x1 0 303 0x1 0 301 0x1>;
			interrupt-names = "vin7_arm_sof", "vin7_arm_last_pixel", "vin7_arm_vsync";
		};

		/* node for vin8 controller */
		dspvin8 {
			compatible = "ambarella,dspvin";
			interrupts = <0 305 0x1 0 306 0x1 0 304 0x1>;
			interrupt-names = "vin8_arm_sof", "vin8_arm_last_pixel", "vin8_arm_vsync";
		};

		/* node for vin9 controller */
		dspvin9 {
			compatible = "ambarella,dspvin";
			interrupts = <0 308 0x1 0 309 0x1 0 307 0x1>;
			interrupt-names = "vin9_arm_sof", "vin9_arm_last_pixel", "vin9_arm_vsync";
		};

		/* node for vin10 controller */
		dspvin10 {
			compatible = "ambarella,dspvin";
			interrupts = <0 311 0x1 0 312 0x1 0 310 0x1>;
			interrupt-names = "vin10_arm_sof", "vin10_arm_last_pixel", "vin10_arm_vsync";
		};

		/* node for vin11 controller */
		dspvin11 {
			compatible = "ambarella,dspvin";
			interrupts = <0 314 0x1 0 315 0x1 0 313 0x1>;
			interrupt-names = "vin11_arm_sof", "vin11_arm_last_pixel", "vin11_arm_vsync";
		};

		/* node for vin12 controller */
		dspvin12 {
			compatible = "ambarella,dspvin";
			interrupts = <0 317 0x1 0 318 0x1 0 316 0x1>;
			interrupt-names = "vin12_arm_sof", "vin12_arm_last_pixel", "vin12_arm_vsync";
		};

		/* node for vin13 controller */
		dspvin13 {
			compatible = "ambarella,dspvin";
			interrupts = <0 320 0x1 0 321 0x1 0 319 0x1>;
			interrupt-names = "vin13_arm_sof", "vin13_arm_last_pixel", "vin13_arm_vsync";
		};

		/* node for vin14 controller */
		dspvin14 {
			compatible = "ambarella,dspvin";
			interrupts = <0 323 0x1 0 324 0x1 0 322 0x1>;
			interrupt-names = "vin14_arm_sof", "vin14_arm_last_pixel", "vin14_arm_vsync";
		};

		/* node for vin15 controller */
		dspvin15 {
			compatible = "ambarella,dspvin";
			interrupts = <0 326 0x1 0 327 0x1 0 325 0x1>;
			interrupt-names = "vin15_arm_sof", "vin15_arm_last_pixel", "vin15_arm_vsync";
		};

		/* node for vin16 controller */
		dspvin16 {
			compatible = "ambarella,dspvin";
			interrupts = <0 329 0x1 0 330 0x1 0 328 0x1>;
			interrupt-names = "vin16_arm_sof", "vin16_arm_last_pixel", "vin16_arm_vsync";
		};

		/* node for vin17 controller */
		dspvin17 {
			compatible = "ambarella,dspvin";
			interrupts = <0 332 0x1 0 333 0x1 0 331 0x1>;
			interrupt-names = "vin17_arm_sof", "vin17_arm_last_pixel", "vin17_arm_vsync";
		};

		/* node for vin18 controller */
		dspvin18 {
			compatible = "ambarella,dspvin";
			interrupts = <0 335 0x1 0 336 0x1 0 334 0x1>;
			interrupt-names = "vin18_arm_sof", "vin18_arm_last_pixel", "vin18_arm_vsync";
		};

		/* node for vin19 controller */
		dspvin19 {
			compatible = "ambarella,dspvin";
			interrupts = <0 338 0x1 0 339 0x1 0 337 0x1>;
			interrupt-names = "vin19_arm_sof", "vin19_arm_last_pixel", "vin19_arm_vsync";
		};

		/* node for vin20 controller */
		dspvin20 {
			compatible = "ambarella,dspvin";
			interrupts = <0 341 0x1 0 342 0x1 0 340 0x1>;
			interrupt-names = "vin20_arm_sof", "vin20_arm_last_pixel", "vin20_arm_vsync";
		};

		/* node for vin21 controller */
		dspvin21 {
			compatible = "ambarella,dspvin";
			interrupts = <0 344 0x1 0 345 0x1 0 343 0x1>;
			interrupt-names = "vin21_arm_sof", "vin21_arm_last_pixel", "vin21_arm_vsync";
		};

		/* node for vin22 controller */
		dspvin22 {
			compatible = "ambarella,dspvin";
			interrupts = <0 347 0x1 0 348 0x1 0 346 0x1>;
			interrupt-names = "vin22_arm_sof", "vin22_arm_last_pixel", "vin22_arm_vsync";
		};

		/* node for vin23 controller */
		dspvin23 {
			compatible = "ambarella,dspvin";
			interrupts = <0 350 0x1 0 351 0x1 0 349 0x1>;
			interrupt-names = "vin23_arm_sof", "vin23_arm_last_pixel", "vin23_arm_vsync";
		};

		/* node for vin24 controller */
		dspvin24 {
			compatible = "ambarella,dspvin";
			interrupts = <0 353 0x1 0 354 0x1 0 352 0x1>;
			interrupt-names = "vin24_arm_sof", "vin24_arm_last_pixel", "vin24_arm_vsync";
		};

		/* node for vin25 controller */
		dspvin25 {
			compatible = "ambarella,dspvin";
			interrupts = <0 357 0x1 0 358 0x1 0 356 0x1>;
			interrupt-names = "vin25_arm_sof", "vin25_arm_last_pixel", "vin25_arm_vsync";
		};

		/* node for vin26 controller */
		dspvin26 {
			compatible = "ambarella,dspvin";
			interrupts = <0 360 0x1 0 361 0x1 0 359 0x1>;
			interrupt-names = "vin26_arm_sof", "vin26_arm_last_pixel", "vin26_arm_vsync";
		};

		/* node for vin27 controller */
		dspvin27 {
			compatible = "ambarella,dspvin";
			interrupts = <0 363 0x1 0 364 0x1 0 362 0x1>;
			interrupt-names = "vin27_arm_sof", "vin27_arm_last_pixel", "vin27_arm_vsync";
		};

		/* node for vin28 controller */
		dspvin28 {
			compatible = "ambarella,dspvin";
			interrupts = <0 366 0x1 0 367 0x1 0 365 0x1>;
			interrupt-names = "vin28_arm_sof", "vin28_arm_last_pixel", "vin28_arm_vsync";
		};

		/* node for vin29 controller */
		dspvin29 {
			compatible = "ambarella,dspvin";
			interrupts = <0 369 0x1 0 370 0x1 0 368 0x1>;
			interrupt-names = "vin29_arm_sof", "vin29_arm_last_pixel", "vin29_arm_vsync";
		};

		/* node for vin30 controller */
		dspvin30 {
			compatible = "ambarella,dspvin";
			interrupts = <0 372 0x1 0 373 0x1 0 371 0x1>;
			interrupt-names = "vin30_arm_sof", "vin30_arm_last_pixel", "vin30_arm_vsync";
		};

		/* node for vin31 controller */
		dspvin31 {
			compatible = "ambarella,dspvin";
			interrupts = <0 375 0x1 0 376 0x1 0 374 0x1>;
			interrupt-names = "vin31_arm_sof", "vin31_arm_last_pixel", "vin31_arm_vsync";
		};

		/* node for vin32 controller */
		dspvin32 {
			compatible = "ambarella,dspvin";
			interrupts = <0 378 0x1 0 379 0x1 0 377 0x1>;
			interrupt-names = "vin32_arm_sof", "vin32_arm_last_pixel", "vin32_arm_vsync";
		};

		/* node for vin33 controller */
		dspvin33 {
			compatible = "ambarella,dspvin";
			interrupts = <0 381 0x1 0 382 0x1 0 380 0x1>;
			interrupt-names = "vin33_arm_sof", "vin33_arm_last_pixel", "vin33_arm_vsync";
		};

		/* node for vin34 controller */
		dspvin34 {
			compatible = "ambarella,dspvin";
			interrupts = <0 384 0x1 0 385 0x1 0 383 0x1>;
			interrupt-names = "vin34_arm_sof", "vin34_arm_last_pixel", "vin34_arm_vsync";
		};

		/* node for vin35 controller */
		dspvin35 {
			compatible = "ambarella,dspvin";
			interrupts = <0 387 0x1 0 388 0x1 0 386 0x1>;
			interrupt-names = "vin35_arm_sof", "vin35_arm_last_pixel", "vin35_arm_vsync";
		};

		/* node for vin36 controller */
		dspvin36 {
			compatible = "ambarella,dspvin";
			interrupts = <0 390 0x1 0 391 0x1 0 389 0x1>;
			interrupt-names = "vin36_arm_sof", "vin36_arm_last_pixel", "vin36_arm_vsync";
		};

		/* node for vin37 controller */
		dspvin37 {
			compatible = "ambarella,dspvin";
			interrupts = <0 393 0x1 0 394 0x1 0 392 0x1>;
			interrupt-names = "vin37_arm_sof", "vin37_arm_last_pixel", "vin37_arm_vsync";
		};

		/* node for vin38 controller */
		dspvin38 {
			compatible = "ambarella,dspvin";
			interrupts = <0 396 0x1 0 397 0x1 0 395 0x1>;
			interrupt-names = "vin38_arm_sof", "vin38_arm_last_pixel", "vin38_arm_vsync";
		};

		/* node for vin39 controller */
		dspvin39 {
			compatible = "ambarella,dspvin";
			interrupts = <0 399 0x1 0 400 0x1 0 398 0x1>;
			interrupt-names = "vin39_arm_sof", "vin39_arm_last_pixel", "vin39_arm_vsync";
		};

		/* node for vin40 controller */
		dspvin40 {
			compatible = "ambarella,dspvin";
			interrupts = <0 402 0x1 0 403 0x1 0 401 0x1>;
			interrupt-names = "vin40_arm_sof", "vin40_arm_last_pixel", "vin40_arm_vsync";
		};

		/* node for vin41 controller */
		dspvin41 {
			compatible = "ambarella,dspvin";
			interrupts = <0 405 0x1 0 406 0x1 0 404 0x1>;
			interrupt-names = "vin41_arm_sof", "vin41_arm_last_pixel", "vin41_arm_vsync";
		};

		/* node for vin42 controller */
		dspvin42 {
			compatible = "ambarella,dspvin";
			interrupts = <0 408 0x1 0 409 0x1 0 407 0x1>;
			interrupt-names = "vin42_arm_sof", "vin42_arm_last_pixel", "vin42_arm_vsync";
		};

		/* node for vin43 controller */
		dspvin43 {
			compatible = "ambarella,dspvin";
			interrupts = <0 411 0x1 0 412 0x1 0 410 0x1>;
			interrupt-names = "vin43_arm_sof", "vin43_arm_last_pixel", "vin43_arm_vsync";
		};

		/* node for vin44 controller */
		dspvin44 {
			compatible = "ambarella,dspvin";
			interrupts = <0 414 0x1 0 415 0x1 0 413 0x1>;
			interrupt-names = "vin44_arm_sof", "vin44_arm_last_pixel", "vin44_arm_vsync";
		};

		/* node for vin45 controller */
		dspvin45 {
			compatible = "ambarella,dspvin";
			interrupts = <0 417 0x1 0 418 0x1 0 416 0x1>;
			interrupt-names = "vin45_arm_sof", "vin45_arm_last_pixel", "vin45_arm_vsync";
		};

		/* node for vin46 controller */
		dspvin46 {
			compatible = "ambarella,dspvin";
			interrupts = <0 420 0x1 0 421 0x1 0 419 0x1>;
			interrupt-names = "vin46_arm_sof", "vin46_arm_last_pixel", "vin46_arm_vsync";
		};

		/* node for vin47 controller */
		dspvin47 {
			compatible = "ambarella,dspvin";
			interrupts = <0 423 0x1 0 424 0x1 0 422 0x1>;
			interrupt-names = "vin47_arm_sof", "vin47_arm_last_pixel", "vin47_arm_vsync";
		};

		/* node for vout0 controller */
		dspvout0 {
			compatible = "ambarella,dspvout";
			interrupts = <0 149 0x1>;
			interrupt-names = "arm_vout_a";
		};

		/* node for vout1 controller */
		dspvout1 {
			compatible = "ambarella,dspvout";
			interrupts = <0 150 0x1>;
			interrupt-names = "arm_vout_b";
		};

		/* node for vout2 controller */
		dspvout2 {
			compatible = "ambarella,dspvout";
			interrupts = <0 151 0x1>;
			interrupt-names = "arm_vout_c";
		};
	};
};
